VERSION ""

NS_ :

BS_:

BU_: VT3 VT2 VT1 Implement

BO_ 2565734142 Nxx: 8 Vector__XXX
 SG_ FirstSpecificParametricId m131 : 16|8@1+ (1,0) [0|0] "" Vector__XXX
 SG_ FirstGeneralParametricId m128 : 8|8@1+ (1,0) [0|0] "" Vector__XXX
 SG_ FirstSpecificParametric m132 : 16|16@1+ (1,0) [0|0] "" Vector__XXX
 SG_ FirstGeneralParametric m129 : 8|16@1+ (1,0) [0|0] "" Vector__XXX
 SG_ FailureReasonCode m194 : 24|8@1+ (1,0) [0|0] "" Vector__XXX
 SG_ Status m194 : 16|2@1+ (1,0) [0|0] "" Vector__XXX
 SG_ NameOfCF m192 : 16|64@1+ (1,0) [0|0] "" Vector__XXX
 SG_ NumberOfSaOrNamePairs m67 : 16|8@1+ (1,0) [0|250] "" Vector__XXX
 SG_ NIECUPort m64 : 8|4@1+ (1,0) [0|15] "" Vector__XXX
 SG_ FilterMode m1 : 16|8@1+ (1,0) [0|255] "" Vector__XXX
 SG_ FromPort m0 : 12|4@1+ (1,0) [0|15] "" Vector__XXX
 SG_ ToPort m0 : 8|4@1+ (1,0) [0|15] "" Vector__XXX
 SG_ ControlByte M : 0|8@1+ (1,0) [0|255] "" Vector__XXX

BO_ 2565799678 ACL: 8 Vector__XXX
 SG_ ArbitraryAddressCapable : 63|1@1+ (1,0) [0|1] "" Vector__XXX
 SG_ IndustryGroup M : 60|3@1+ (1,0) [0|7] "" Vector__XXX
 SG_ VehicleSystemInstance : 56|4@1+ (1,0) [0|15] "" Vector__XXX
 SG_ VehicleSystem m0 : 49|7@1+ (1,0) [0|127] "" Vector__XXX
 SG_ VehicleSystem5 m5 : 49|7@1+ (1,0) [0|127] "" Vector__XXX
 SG_ VehicleSystem4 m4 : 49|7@1+ (1,0) [0|127] "" Vector__XXX
 SG_ VehicleSystem3 m3 : 49|7@1+ (1,0) [0|127] "" Vector__XXX
 SG_ VehicleSystem2 m2 : 49|7@1+ (1,0) [0|127] "" Vector__XXX
 SG_ VehicleSystem1 m1 : 49|7@1+ (1,0) [0|127] "" Vector__XXX
 SG_ Function : 40|8@1+ (1,0) [0|255] "" Vector__XXX
 SG_ FunctionInstance : 35|5@1+ (1,0) [0|31] "" Vector__XXX
 SG_ ECUInstance : 32|3@1+ (1,0) [0|7] "" Vector__XXX
 SG_ ManufacturerCode : 21|11@1+ (1,0) [0|2047] "" Vector__XXX
 SG_ IdentityNumber : 0|21@1+ (1,0) [0|2097152] "" Vector__XXX

BO_ 2566838526 CA: 9 Vector__XXX
 SG_ AddressAssignment : 64|8@1+ (1,0) [0|255] "" Vector__XXX
 SG_ ArbitraryAddressCapable : 63|1@1+ (1,0) [0|1] "" Vector__XXX
 SG_ IndustryGroup M : 60|3@1+ (1,0) [0|7] "" Vector__XXX
 SG_ VehicleSystemInstance : 56|4@1+ (1,0) [0|15] "" Vector__XXX
 SG_ VehicleSystem1 m1 : 49|7@1+ (1,0) [0|127] "" Vector__XXX
 SG_ VehicleSystem2 m2 : 49|7@1+ (1,0) [0|127] "" Vector__XXX
 SG_ VehicleSystem3 m3 : 49|7@1+ (1,0) [0|127] "" Vector__XXX
 SG_ VehicleSystem4 m4 : 49|7@1+ (1,0) [0|127] "" Vector__XXX
 SG_ VehicleSystem5 m5 : 49|7@1+ (1,0) [0|127] "" Vector__XXX
 SG_ VehicleSystem m0 : 49|7@1+ (1,0) [0|127] "" Vector__XXX
 SG_ Function : 40|8@1+ (1,0) [0|255] "" Vector__XXX
 SG_ FunctionInstance : 35|5@1+ (1,0) [0|31] "" Vector__XXX
 SG_ ECUInstance : 32|3@1+ (1,0) [0|7] "" Vector__XXX
 SG_ ManufacturerCode : 21|11@1+ (1,0) [0|2047] "" Vector__XXX
 SG_ IdentityNumber : 0|21@1+ (1,0) [0|2097152] "" Vector__XXX

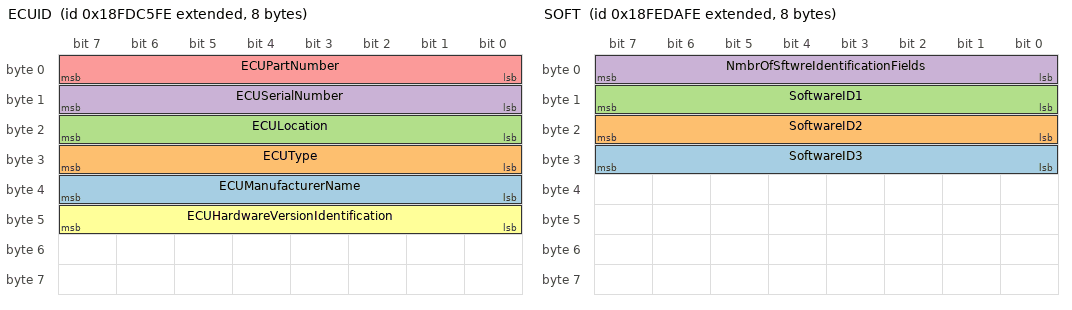
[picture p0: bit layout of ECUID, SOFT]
BO_ 2566768126 ECUID: 8 Vector__XXX
 SG_ ECUManufacturerName : 32|8@1+ (1,0) [0|255] "" Vector__XXX
 SG_ ECUType : 24|8@1+ (1,0) [0|255] "" Vector__XXX
 SG_ ECULocation : 16|8@1+ (1,0) [0|255] "" Vector__XXX
 SG_ ECUSerialNumber : 8|8@1+ (1,0) [0|255] "" Vector__XXX
 SG_ ECUPartNumber : 0|8@1+ (1,0) [0|255] "" Vector__XXX
 SG_ ECUHardwareVersionIdentification : 40|8@1+ (1,0) [0|255] "" Vector__XXX

BO_ 2566839038 SOFT: 8 Vector__XXX
 SG_ SoftwareID3 : 24|8@1+ (1,0) [0|255] "" Vector__XXX
 SG_ SoftwareID2 : 16|8@1+ (1,0) [0|255] "" Vector__XXX
 SG_ SoftwareID1 : 8|8@1+ (1,0) [0|255] "" Vector__XXX
 SG_ NmbrOfSftwreIdentificationFields : 0|8@1+ (1,0) [0|250] "steps" Vector__XXX

BO_ 2566834942 DM1: 22 Vector__XXX
 SG_ DTC5 : 144|32@1+ (1,0) [0|4294967295] "" Vector__XXX
 SG_ DTC4 : 112|32@1+ (1,0) [0|4294967295] "" Vector__XXX
 SG_ DTC3 : 80|32@1+ (1,0) [0|4294967295] "" Vector__XXX
 SG_ DTC2 : 48|32@1+ (1,0) [0|4294967295] "" Vector__XXX
 SG_ DTC1 : 16|32@1+ (1,0) [0|4294967295] "" Vector__XXX

BO_ 2566835198 DM2: 22 Vector__XXX
 SG_ DTC5 : 144|32@1+ (1,0) [0|4294967295] "" Vector__XXX
 SG_ DTC4 : 112|32@1+ (1,0) [0|4294967295] "" Vector__XXX
 SG_ DTC3 : 80|32@1+ (1,0) [0|4294967295] "" Vector__XXX
 SG_ DTC2 : 48|32@1+ (1,0) [0|4294967295] "" Vector__XXX
 SG_ DTC1 : 16|32@1+ (1,0) [0|4294967295] "" Vector__XXX

BO_ 2566734590 ICC: 8 Vector__XXX
 SG_ CertLaboratoryType_FirstDef m0 : 9|3@1+ (1,0) [0|7] "" Vector__XXX
 SG_ TestProtocolRevision_MSBits m1 : 11|2@1+ (1,0) [0|0] "" Vector__XXX
 SG_ MessageRevision M : 47|1@1+ (1,0) [0|0] "" Vector__XXX
 SG_ CertificationReferenceNumber : 48|16@1+ (1,0) [0|65535] "" Vector__XXX
 SG_ CertTypeTaskController m0 : 39|1@1+ (1,0) [0|1] "" Vector__XXX
 SG_ CertTypeTCWorkingSetMaster m0 : 38|1@1+ (1,0) [0|1] "" Vector__XXX
 SG_ CertTypeTCWorkingSetMember m0 : 37|1@1+ (1,0) [0|1] "" Vector__XXX
 SG_ CertTypeFileServer m0 : 36|1@1+ (1,0) [0|1] "" Vector__XXX
 SG_ CertTypeGPSReceiver m0 : 35|1@1+ (1,0) [0|1] "" Vector__XXX
 SG_ CertTypeMinimumECU m0 : 31|1@1+ (1,0) [0|1] "" Vector__XXX
 SG_ CertTypeTECUClass1 m0 : 30|1@1+ (1,0) [0|1] "" Vector__XXX
 SG_ CertTypeTECUClass2 m0 : 29|1@1+ (1,0) [0|1] "" Vector__XXX
 SG_ CertTypeTECUClass3 m0 : 28|1@1+ (1,0) [0|1] "" Vector__XXX
 SG_ CertTypeClass3ECU m0 : 27|1@1+ (1,0) [0|1] "" Vector__XXX
 SG_ CertTypeVirtualTerminal m0 : 26|1@1+ (1,0) [0|1] "" Vector__XXX
 SG_ CertTypeVTWorkingSetMaster m0 : 25|1@1+ (1,0) [0|1] "" Vector__XXX
 SG_ CertTypeVTWorkingSetMember m0 : 24|1@1+ (1,0) [0|1] "" Vector__XXX
 SG_ CertificationLaboratoryID : 13|11@1+ (1,0) [0|2047] "" Vector__XXX
 SG_ CertLaboratoryType_SecondDef m1 : 9|2@1+ (1,0) [0|3] "" Vector__XXX
 SG_ TestProtocolRevision : 6|3@1+ (1,0) [0|7] "" Vector__XXX
 SG_ TestProtocolPublicationYear : 0|6@1+ (1,2000) [2000|2061] "year" Vector__XXX

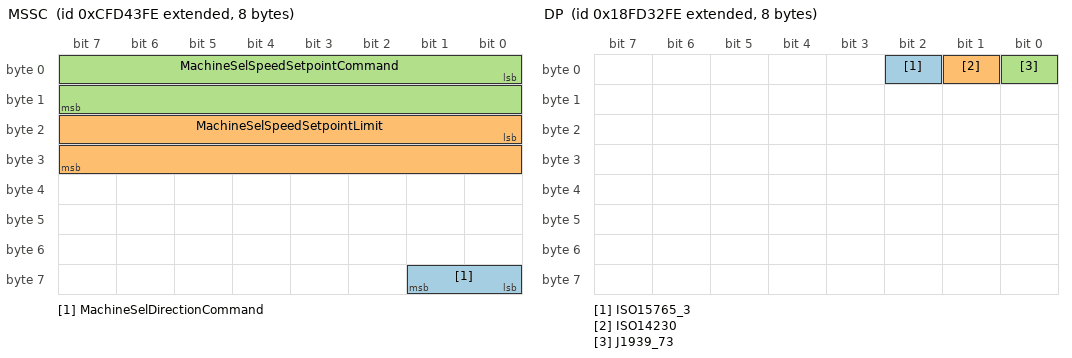
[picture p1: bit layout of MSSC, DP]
BO_ 2365408254 MSSC: 8 Vector__XXX
 SG_ MachineSelDirectionCommand : 56|2@1+ (1,0) [0|3] "" Vector__XXX
 SG_ MachineSelSpeedSetpointLimit : 16|16@1+ (0.001,0) [0|64255] "m/s" Vector__XXX
 SG_ MachineSelSpeedSetpointCommand : 0|16@1+ (0.001,0) [0|64255] "m/s" Vector__XXX

BO_ 2566730494 DP: 8 Vector__XXX
 SG_ ISO15765_3 : 2|1@1+ (1,0) [0|1] "" Vector__XXX
 SG_ ISO14230 : 1|1@1+ (1,0) [0|1] "" Vector__XXX
 SG_ J1939_73 : 0|1@1+ (1,0) [0|1] "" Vector__XXX

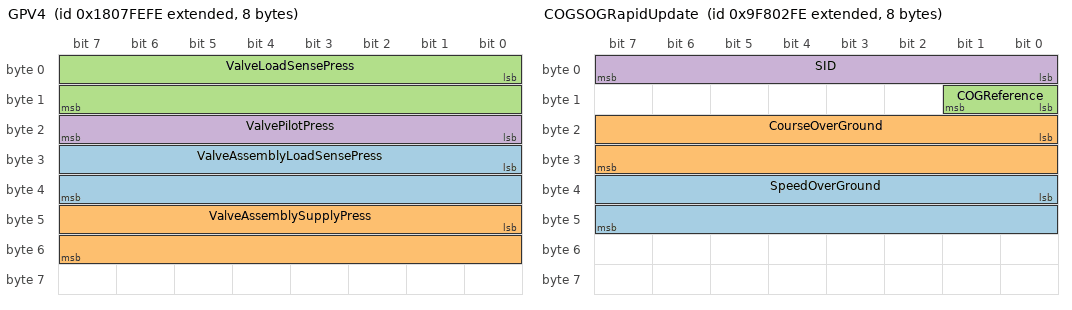
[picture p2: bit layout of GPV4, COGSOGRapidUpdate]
BO_ 2550660862 GPV4: 8 Vector__XXX
 SG_ ValveAssemblyLoadSensePress : 24|16@1+ (5,0) [0|321275] "kPa" Vector__XXX
 SG_ ValveAssemblySupplyPress : 40|16@1+ (5,0) [0|321275] "kPa" Vector__XXX
 SG_ ValveLoadSensePress : 0|16@1+ (5,0) [0|321275] "kPa" Vector__XXX
 SG_ ValvePilotPress : 16|8@1+ (16,0) [0|4000] "kPa" Vector__XXX

BO_ 2364547838 MSS: 9 Vector__XXX
 SG_ MachineSelectedSpeedLimitStatus : 61|3@1+ (1,0) [0|7] "" Vector__XXX
 SG_ MachineSelectedSpeedSource : 58|3@1+ (1,0) [0|7] "" Vector__XXX
 SG_ MachineSelectedDirection : 56|2@1+ (1,0) [0|3] "" Vector__XXX
 SG_ MachineSelectedDistance : 16|32@1+ (0.001,0) [0|4211081.215] "m" Vector__XXX
 SG_ MachineSelectedSpeed : 0|16@1+ (0.001,0) [0|65.535] "m/s" Vector__XXX

BO_ 2566835454 DM3: 0 Vector__XXX

BO_ 2365391616 IOS: 8 Vector__XXX
 SG_ ImplementOperatingStateCmd : 56|2@1+ (1,0) [0|3] "" Vector__XXX

BO_ 2365391360 AISO: 8 Vector__XXX
 SG_ StopAllImplOpTransitionNum : 48|8@1+ (1,0) [0|0] "" Vector__XXX
 SG_ StopAllImplementOperations : 56|2@1- (1,0) [0|3] "" Vector__XXX

BO_ 2314732286 COGSOGRapidUpdate: 8 Vector__XXX
 SG_ SpeedOverGround : 32|16@1+ (0.01,0) [0|655.32] "m/s" Vector__XXX
 SG_ CourseOverGround : 16|16@1+ (0.0001,0) [0|6.28318] "rad" Vector__XXX
 SG_ COGReference : 8|2@1+ (1,0) [0|3] "" Vector__XXX
 SG_ SID : 0|8@1+ (1,0) [0|252] "" Vector__XXX

BO_ 2358181630 SCMCC: 8 Vector__XXX
 SG_ MaxDesignatorStringLength m144 : 32|16@1+ (1,0) [0|65535] "" Vector__XXX
 SG_ BusyFlagParsing m149 : 33|1@1+ (1,0) [0|1] "" Vector__XXX
 SG_ ReceivedTAN m50 : 32|8@1+ (1,0) [0|255] "" Vector__XXX
 SG_ RecordedFunctionValue m51 : 32|32@1+ (1,0) [0|4294967295] "" Vector__XXX
 SG_ BusyFlagMemoryAccess m149 : 32|1@1+ (1,0) [0|1] "" Vector__XXX
 SG_ ExecutionIndicationResponseError m50 : 24|8@1+ (1,0) [0|255] "" Vector__XXX
 SG_ TAN m51 : 24|8@1+ (1,0) [0|255] "" Vector__XXX
 SG_ SequenceState m149 : 24|8@1+ (1,0) [0|255] "" Vector__XXX
 SG_ ReasonIndicator m48 : 24|8@1+ (1,0) [0|255] "" Vector__XXX
 SG_ GraphicsHeight m144 : 24|8@1+ (1,0) [32|255] "" Vector__XXX
 SG_ FunctionExecutionState m50 : 22|2@1+ (1,0) [0|3] "" Vector__XXX
 SG_ FunctionExecutionStateAck m52 : 22|2@1+ (1,0) [0|3] "" Vector__XXX
 SG_ StateID m50 : 16|6@1+ (1,0) [0|63] "" Vector__XXX
 SG_ ActualConfigurationLabel m0 : 16|8@1+ (1,0) [0|255] "" Vector__XXX
 SG_ ActualVersionLabel m0 : 16|8@1+ (1,0) [0|255] "" Vector__XXX
 SG_ GraphicsWidth m144 : 16|8@1+ (1,0) [32|255] "" Vector__XXX
 SG_ RecordedStateID m51 : 16|6@1+ (1,0) [0|63] "" Vector__XXX
 SG_ SequenceNumber m149 : 16|8@1+ (1,0) [0|255] "" Vector__XXX
 SG_ ObjectIdOfFirstFaultyObject m4 : 16|16@1+ (1,0) [0|65535] "" Vector__XXX
 SG_ RecordedFunctionID m51 : 8|8@1+ (1,0) [0|255] "" Vector__XXX
 SG_ MemoryStatus m145 : 8|8@1+ (1,0) [0|1] "" Vector__XXX
 SG_ VersionResponseError m1M : 8|8@1+ (1,0) [0|255] "" Vector__XXX
 SG_ ConfigLabelResponseError m2M : 8|8@1+ (1,0) [0|255] "" Vector__XXX
 SG_ TransferResponseError m3 : 8|8@1+ (1,0) [0|255] "" Vector__XXX
 SG_ ActivationResponseError m4 : 8|8@1+ (1,0) [0|255] "" Vector__XXX
 SG_ SCMState m149 : 8|8@1+ (1,0) [0|2] "" Vector__XXX
 SG_ FunctionID m50 : 8|8@1+ (1,0) [0|255] "" Vector__XXX
 SG_ SCVersion m144 : 8|8@1+ (1,0) [0|255] "" Vector__XXX
 SG_ CommandedSCCState m48 : 8|8@1+ (1,0) [0|1] "" Vector__XXX
 SG_ DeleteCommandResponseError m5 : 8|8@1+ (1,0) [0|255] "" Vector__XXX
 SG_ StoreCommandError m6 : 8|8@1+ (1,0) [0|255] "" Vector__XXX
 SG_ LoadResponseError m7 : 8|8@1+ (1,0) [0|255] "" Vector__XXX
 SG_ MessageCode M : 0|8@1+ (1,0) [0|255] "" Vector__XXX

BO_ 2358116094 SCCCM: 8 Vector__XXX
 SG_ OperatorConfirmationRequired3 m3 : 63|1@1+ (1,0) [0|1] "" Vector__XXX
 SG_ ClientFunctionErrorStatuts3 m3 : 56|4@1+ (1,0) [0|15] "" Vector__XXX
 SG_ IDOfFaultyClientFunction3 m3 : 48|8@1+ (1,0) [0|255] "" Vector__XXX
 SG_ OperatorConfirmationRequired2 m2 : 47|1@1+ (1,0) [0|1] "" Vector__XXX
 SG_ ClientFunctionErrorStatuts2 m2 : 40|4@1+ (1,0) [0|15] "" Vector__XXX
 SG_ ReceivedTAN m52 : 32|8@1+ (1,0) [0|255] "" Vector__XXX
 SG_ FunctionValue m0 : 32|32@1+ (1,0) [0|4294967295] "" Vector__XXX
 SG_ IDOfFaultyClientFunction2 m2 : 32|8@1+ (1,0) [0|255] "" Vector__XXX
 SG_ ClientFunctonErrorState m150 : 32|8@1+ (1,0) [0|255] "" Vector__XXX
 SG_ OperatorConfirmationRequired1 m1 : 31|1@1+ (1,0) [0|1] "" Vector__XXX
 SG_ TAN m50 : 24|8@1+ (1,0) [0|255] "" Vector__XXX
 SG_ ClientExecutionError m52 : 24|8@1+ (1,0) [0|255] "" Vector__XXX
 SG_ ClientFunctionErrorStatuts1 m1 : 24|4@1+ (1,0) [0|15] "" Vector__XXX
 SG_ ClientAbortError m49 : 24|8@1+ (1,0) [0|255] "" Vector__XXX
 SG_ SequenceState m150 : 24|8@1+ (1,0) [0|255] "" Vector__XXX
 SG_ FunctionExecutionState m50M : 22|2@1+ (1,0) [0|3] "" Vector__XXX
 SG_ NewFunctionExecutionState m52 : 22|2@1+ (1,0) [0|3] "" Vector__XXX
 SG_ NewStateID m52 : 16|6@1+ (1,0) [0|63] "" Vector__XXX
 SG_ IDOfFaultyClientFunction1 m1 : 16|8@1+ (1,0) [0|255] "" Vector__XXX
 SG_ StateID m50 : 16|6@1+ (1,0) [0|63] "" Vector__XXX
 SG_ SequenceNumber m150 : 16|8@1+ (1,0) [0|255] "" Vector__XXX
 SG_ NumberOfFaultyFunctions m53M : 8|8@1+ (1,0) [0|255] "" Vector__XXX
 SG_ RecordedFunctionID m52 : 8|8@1+ (1,0) [0|255] "" Vector__XXX
 SG_ SCCState m150 : 8|8@1+ (1,0) [0|2] "" Vector__XXX
 SG_ FunctionID m50 : 8|8@1+ (1,0) [0|255] "" Vector__XXX
 SG_ MemoryRequired m145 : 8|32@1+ (1,0) [0|4294967295] "bytes" Vector__XXX
 SG_ AddressSCCWSM m4 : 8|8@1+ (1,0) [0|253] "" Vector__XXX
 SG_ DeleteCommandType m5 : 8|8@1+ (1,0) [0|1] "" Vector__XXX
 SG_ MessageCode M : 0|8@1+ (1,0) [0|255] "" Vector__XXX

BO_ 2559835902 NM: 8 Vector__XXX
 SG_ ManufacturerCodeQualifierFlag m0 : 8|1@1+ (1,0) [0|1] "" Vector__XXX
 SG_ ECUInstanceQualifierFlag m0 : 9|1@1+ (1,0) [0|1] "" Vector__XXX
 SG_ FunctionInstanceQualifierFlag m0 : 10|1@1+ (1,0) [0|1] "" Vector__XXX
 SG_ FunctionQualifierFlag m0 : 11|1@1+ (1,0) [0|1] "" Vector__XXX
 SG_ VehicleSystemQualifierFlag m0 : 12|1@1+ (1,0) [0|1] "" Vector__XXX
 SG_ VehicleSystemInstanceQualifierFl m0 : 13|1@1+ (1,0) [0|1] "" Vector__XXX
 SG_ IndustryGroupQualifierFlag m0 : 14|1@1+ (1,0) [0|1] "" Vector__XXX
 SG_ ArbitraryAddressCapableQualifier m0 : 15|1@1+ (1,0) [0|1] "" Vector__XXX
 SG_ NMControlModeIndicator M : 16|4@1+ (1,0) [0|15] "" Vector__XXX
 SG_ CommandManufacturerCode m0 : 21|11@1+ (1,0) [0|2047] "" Vector__XXX
 SG_ CommandECUInstance m0 : 32|3@1+ (1,0) [0|7] "" Vector__XXX
 SG_ CommandFunctionInstance m0 : 35|5@1+ (1,0) [0|31] "" Vector__XXX
 SG_ CommandFunction m0 : 40|8@1+ (1,0) [0|255] "" Vector__XXX
 SG_ CommandVehicleSystem m0 : 49|7@1+ (1,0) [0|127] "" Vector__XXX
 SG_ CommandIndustryGroup m0 : 60|3@1+ (1,0) [0|7] "" Vector__XXX
 SG_ CommandVehicleSystemInstance m0 : 56|4@1+ (1,0) [0|15] "" Vector__XXX
 SG_ CommandArbitraryAddressCapable m0 : 63|1@1+ (1,0) [0|1] "" Vector__XXX
 SG_ ErrorCode m4 : 0|8@1+ (1,0) [0|0] "" Vector__XXX
 SG_ NameChecksum m0 : 0|8@1+ (1,0) [0|0] "" Vector__XXX

BO_ 2566843646 VI: 8 Vector__XXX
 SG_ VehicleIdentificationNumber : 0|8@1+ (1,0) [0|255] "per byte" Vector__XXX

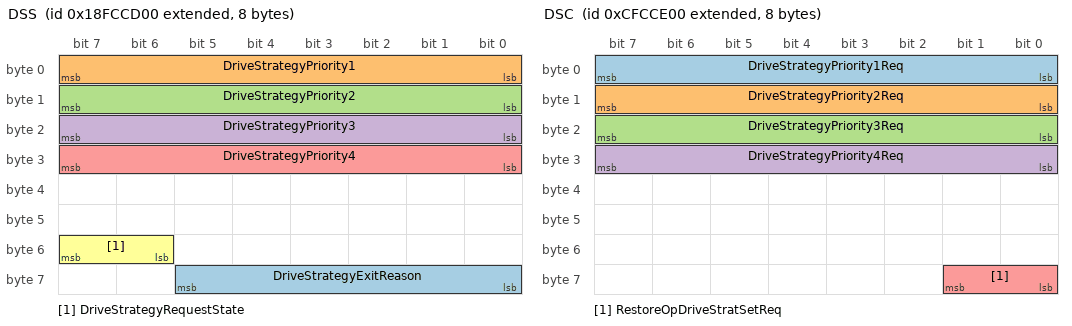
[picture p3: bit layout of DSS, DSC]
BO_ 2566704384 DSS: 8 Vector__XXX
 SG_ DriveStrategyExitReason : 56|6@1+ (1,0) [0|63] "" Vector__XXX
 SG_ DriveStrategyPriority1 : 0|8@1+ (1,0) [0|255] "" Vector__XXX
 SG_ DriveStrategyPriority2 : 8|8@1+ (1,0) [0|255] "" Vector__XXX
 SG_ DriveStrategyPriority3 : 16|8@1+ (1,0) [0|255] "" Vector__XXX
 SG_ DriveStrategyPriority4 : 24|8@1+ (1,0) [0|255] "" Vector__XXX
 SG_ DriveStrategyRequestState : 54|2@1+ (1,0) [0|3] "" Vector__XXX

BO_ 2365378048 DSC: 8 Vector__XXX
 SG_ DriveStrategyPriority1Req : 0|8@1+ (1,0) [0|255] "" Vector__XXX
 SG_ DriveStrategyPriority2Req : 8|8@1+ (1,0) [0|255] "" Vector__XXX
 SG_ DriveStrategyPriority3Req : 16|8@1+ (1,0) [0|255] "" Vector__XXX
 SG_ DriveStrategyPriority4Req : 24|8@1+ (1,0) [0|255] "" Vector__XXX
 SG_ RestoreOpDriveStratSetReq : 56|2@1+ (1,0) [0|3] "" Vector__XXX

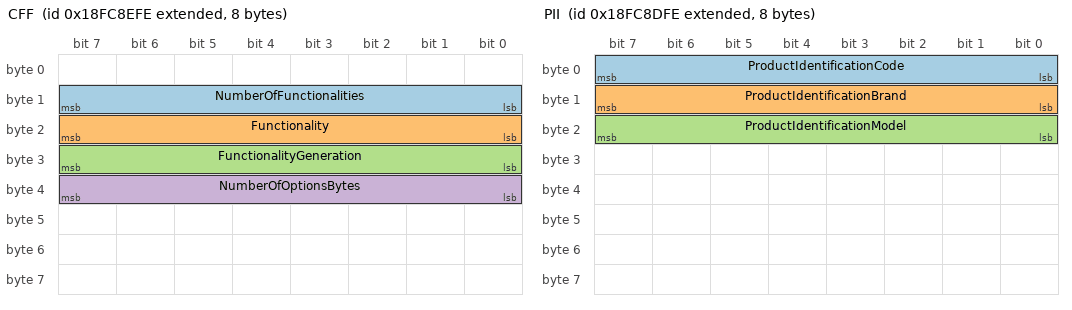
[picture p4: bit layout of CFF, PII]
BO_ 2566688510 CFF: 8 Vector__XXX
 SG_ NumberOfFunctionalities : 8|8@1- (1,0) [1|255] "" Vector__XXX
 SG_ Functionality : 16|8@1- (1,0) [0|255] "" Vector__XXX
 SG_ FunctionalityGeneration : 24|8@1- (1,0) [1|255] "" Vector__XXX
 SG_ NumberOfOptionsBytes : 32|8@1- (1,0) [0|255] "" Vector__XXX

BO_ 2566688254 PII: 8 Vector__XXX
 SG_ ProductIdentificationCode : 0|8@1- (1,0) [0|0] "" Vector__XXX
 SG_ ProductIdentificationBrand : 8|8@1- (1,0) [0|0] "" Vector__XXX
 SG_ ProductIdentificationModel : 16|8@1- (1,0) [0|0] "" Vector__XXX

CM_ BO_ 2565734142 "Used to access network interconnection ECU parametrics and database";
CM_ SG_ 2565734142 NumberOfSaOrNamePairs "The number of instances of Source Addresses and associated NAMEs included in the associated data content.";
CM_ SG_ 2565734142 NIECUPort "Port for Network PG";
CM_ SG_ 2565734142 FilterMode "Filter mode for Network PG";
CM_ SG_ 2565734142 FromPort "Source port for Network PG";
CM_ SG_ 2565734142 ToPort "Destination port for network PG";
CM_ BO_ 2565799678 "Address Claimed";
CM_ BO_ 2566838526 "Commanded Address";
CM_ SG_ 2566838526 AddressAssignment "The source address that is to be assigned to the CA that has the NAME corresponding to the one conveyed in the first eight bytes of this Commanded Address message.";
CM_ BO_ 2566768126 "ECU Identification Information";
CM_ SG_ 2566768126 ECULocation "The location of the ECU within a network.";
CM_ SG_ 2566768126 ECUSerialNumber "The serial number of the physical ECU.";
CM_ SG_ 2566768126 ECUPartNumber "The part number of the physical ECU.";
CM_ SG_ 2566768126 ECUHardwareVersionIdentification "The part number of the physical ECU.";
CM_ BO_ 2566839038 "Software Identification";
CM_ SG_ 2566839038 SoftwareID3 "Software ID";
CM_ SG_ 2566839038 SoftwareID2 "Software ID";
CM_ SG_ 2566839038 SoftwareID1 "Software ID";
CM_ SG_ 2566839038 NmbrOfSftwreIdentificationFields "Number of software identification designators represented in the software identification parameter group.";
CM_ BO_ 2566834942 "Active diagnostic trouble codes";
CM_ SG_ 2566834942 DTC5 "Diagnostic Trouble Code";
CM_ SG_ 2566834942 DTC4 "Diagnostic Trouble Code";
CM_ SG_ 2566834942 DTC3 "Diagnostic Trouble Code";
CM_ SG_ 2566834942 DTC2 "Diagnostic Trouble Code";
CM_ SG_ 2566834942 DTC1 "Diagnostic Trouble Code";
CM_ BO_ 2566835198 "Previously active diagnostic trouble codes";
CM_ SG_ 2566835198 DTC5 "Diagnostic Trouble Code";
CM_ SG_ 2566835198 DTC4 "Diagnostic Trouble Code";
CM_ SG_ 2566835198 DTC3 "Diagnostic Trouble Code";
CM_ SG_ 2566835198 DTC2 "Diagnostic Trouble Code";
CM_ SG_ 2566835198 DTC1 "Diagnostic Trouble Code";
CM_ BO_ 2566734590 "ISOBUS compliance certification";
CM_ SG_ 2566734590 CertLaboratoryType_FirstDef "Approving body for the certification laboratory.";
CM_ SG_ 2566734590 MessageRevision "This parameter distinguishes the format of the ISOBUS Compliance Certification message in the second 
edition from the format in the third and later editions.";
CM_ SG_ 2566734590 CertificationReferenceNumber "ISOBUS Compliance certification reference number";
CM_ SG_ 2566734590 CertTypeTaskController "ISOBUS Compliance certification type - Task Controller";
CM_ SG_ 2566734590 CertTypeTCWorkingSetMaster "ISOBUS Compliance certification type - TC working set master";
CM_ SG_ 2566734590 CertTypeTCWorkingSetMember "ISOBUS Compliance certification type - TC working set member";
CM_ SG_ 2566734590 CertTypeFileServer "ISOBUS Compliance certification type - File server";
CM_ SG_ 2566734590 CertTypeGPSReceiver "ISOBUS Compliance certification type - GPS receiver";
CM_ SG_ 2566734590 CertTypeMinimumECU "ISOBUS Compliance certification type - Minimum ECU";
CM_ SG_ 2566734590 CertTypeTECUClass1 "ISOBUS Compliance certification type - TECU Class 1";
CM_ SG_ 2566734590 CertTypeTECUClass2 "ISOBUS Compliance certification type - TECU Class 2";
CM_ SG_ 2566734590 CertTypeTECUClass3 "ISOBUS Compliance certification type - TECU Class 3";
CM_ SG_ 2566734590 CertTypeClass3ECU "ISOBUS Compliance certification type - Class 3 ECU";
CM_ SG_ 2566734590 CertTypeVirtualTerminal "ISOBUS Compliance certification type - Virtual terminal";
CM_ SG_ 2566734590 CertTypeVTWorkingSetMaster "ISOBUS Compliance certification type - VT working set master";
CM_ SG_ 2566734590 CertTypeVTWorkingSetMember "ISOBUS Compliance certification type - VT working set member";
CM_ SG_ 2566734590 CertificationLaboratoryID "ISOBUS Compliance certification laboratory ID";
CM_ SG_ 2566734590 CertLaboratoryType_SecondDef "Approving body for the certification laboratory.";
CM_ SG_ 2566734590 TestProtocolRevision "ISOBUS compliance certificate revision";
CM_ SG_ 2566734590 TestProtocolPublicationYear "ISOBUS compliance certification year";
CM_ BO_ 2365408254 "Machine Selected Speed Command";
CM_ SG_ 2365408254 MachineSelDirectionCommand "Machine selected direction command";
CM_ SG_ 2365408254 MachineSelSpeedSetpointLimit "Machine selected speed setpoint limit";
CM_ SG_ 2365408254 MachineSelSpeedSetpointCommand "Machine selected speed setpoint command";
CM_ BO_ 2566730494 "ECU diagnostic protocol";
CM_ SG_ 2566730494 ISO15765_3 "ISO 15765-3 (UDS on CAN)";
CM_ SG_ 2566730494 ISO14230 "ISO 14230 (KWP 2000 over K line)";
CM_ SG_ 2566730494 J1939_73 "J1939-73";
CM_ BO_ 2550660862 "General purpose valve load sense pressure";
CM_ SG_ 2550660862 ValveAssemblyLoadSensePress "The maximum pressure of a valve assembly's current collective load sense pressures where a valve assembly can ...";
CM_ SG_ 2550660862 ValveAssemblySupplyPress "Pressure of the hydraulic supply port to a valve assembly.";
CM_ SG_ 2550660862 ValveLoadSensePress "The maximum of the currently measured pressures of a valve's work port A and work port B.";
CM_ SG_ 2550660862 ValvePilotPress "Pressure of a valve's pilot supply port.";
CM_ BO_ 2364547838 "Machine selected speed";
CM_ SG_ 2364547838 MachineSelectedSpeedLimitStatus "Machine selected speed limit status";
CM_ SG_ 2364547838 MachineSelectedSpeedSource "Machine selected speed source";
CM_ SG_ 2364547838 MachineSelectedDirection "Machine selected direction";
CM_ SG_ 2364547838 MachineSelectedDistance "Machine selected Distance";
CM_ SG_ 2364547838 MachineSelectedSpeed "Machine selected Speed";
CM_ BO_ 2566835454 "Diagnostic data clear/reset of previously active DTCs.";
CM_ BO_ 2365391616 "Implement operating state command";
CM_ BO_ 2365391360 " All implements stop operations switch state";
CM_ SG_ 2365391360 StopAllImplOpTransitionNum "This parameter indicates the number of transitions from Permit (01) to Stop (00) since power up of 
the Stop all implement operations parameter. The parameter resets to zero on the next transition after 
reporting the maximum value.";
CM_ BO_ 2314732286 "This PGN is a single frame PGN that provides Course Over Ground(COG)and Speed Over Ground(SOG).

Being a single frame Msg,as opposed to other PGNs that include COG and SOG and are defined as multi-packet,this PGN lends itself to being transmitted more f";
CM_ SG_ 2314732286 CourseOverGround "The direction of the path over ground actually followed by a vessel.";
CM_ SG_ 2314732286 COGReference "0 = True, 
1 = Magnetic, 
2 = Error, 
3 = Null";
CM_ SG_ 2314732286 SID "An upward counting number used to tie related information together between different PGNs.For example,SID would be used to tie together COG,SOG and RAIM values to a given Pos.255=no valid Pos fix to tie it to.Range 0 to 250 for valid Pos fixes.";
CM_ BO_ 2358181630 "Sequence Control Master to Sequence Control Client";
CM_ SG_ 2358181630 MaxDesignatorStringLength "Maximum number of displayed characters for designator strings";
CM_ SG_ 2358181630 GraphicsHeight "Number of pixels on the Y axis for graphics objects";
CM_ SG_ 2358181630 GraphicsWidth "Number of pixels on the X axis for graphics objects";
CM_ SG_ 2358181630 ObjectIdOfFirstFaultyObject "Object ID of first faulty object";
CM_ SG_ 2358181630 MemoryStatus "Status of the SCMasterMemoryResponse";
CM_ SG_ 2358181630 VersionResponseError "Error code of the SCDVersionResponse";
CM_ SG_ 2358181630 ConfigLabelResponseError "Error code of SCDConfigurationLabelResponse";
CM_ SG_ 2358181630 TransferResponseError "Error code of the SCDTransferResponse";
CM_ SG_ 2358181630 SCMState "State of sending SCM";
CM_ SG_ 2358181630 SCVersion "Version of supported SC standard";
CM_ SG_ 2358181630 MessageCode "Message code of the SCMCC message";
CM_ BO_ 2358116094 "Sequence Control Client to Sequence Control Master";
CM_ SG_ 2358116094 ClientAbortError "Error code of a SCClientAbort";
CM_ SG_ 2358116094 MemoryRequired "Volatile memory required, number of bytes of the SCD to upload";
CM_ SG_ 2358116094 AddressSCCWSM "Source address of SCC's working set master";
CM_ BO_ 2566843646 "Byte: 1-n Vehicle Identification Number 
Delimiter (ASCII “*”)";
CM_ SG_ 2566843646 VehicleIdentificationNumber "Vehicle Identification Number (VIN) as assigned by the vehicle manufacturer.";
CM_ BO_ 2566704384 "Message sent from the tractor to the implement to indicate the current status, of the drive strategy priority 
structure, which indicates the priority of the multiple powertrain functions. ";
CM_ SG_ 2566704384 DriveStrategyExitReason "Parameter used to indicate why the drive strategy subsystem cannot currently accept remote commands or 
has most recently stopped accepting remote commands.";
CM_ SG_ 2566704384 DriveStrategyPriority1 "This parameter indicates the current Tractor drive strategy priority structure, which determines the balance 
between  fuel  economy/consumption  and  the  torque  reserve  of  the  engine.  This  parameter  indicates  the 
highest priority. ";
CM_ SG_ 2566704384 DriveStrategyPriority2 "This parameter indicates the current Tractor drive strategy priority structure, which determines the balance 
between  fuel  economy/consumption  and  the  torque  reserve  of  the  engine.  This  parameter  indicates 
 the second to highest priority. ";
CM_ SG_ 2566704384 DriveStrategyPriority3 "This parameter indicates the current Tractor drive strategy priority structure, which determines the balance 
between  fuel  economy/consumption  and  the  torque  reserve  of  the  engine.  This  parameter  indicates 
 the third to highest priority. ";
CM_ SG_ 2566704384 DriveStrategyPriority4 "This parameter indicates the current Tractor drive strategy priority structure, which determines the balance 
between  fuel  economy/consumption  and  the  torque  reserve  of  the  engine.  This  parameter  indicates  the 
lowest priority. ";
CM_ SG_ 2566704384 DriveStrategyRequestState "This  parmeter  reports  the  tractor's  state  associated  with  Drive  Strategy  requests  that  are 
transient/temporary/one-shot.";
CM_ SG_ 2365378048 DriveStrategyPriority1Req "This parameter used to request an alteration to the tractor drive strategy priority structure, which determines 
the  balance  between  fuel  economy/consumption  and  the  torque  reserve  of  the  engine - the highest priority request.";
CM_ SG_ 2365378048 DriveStrategyPriority2Req "This parameter used to request an alteration to the tractor drive strategy priority structure, which determines 
the  balance  between  fuel  economy/consumption  and  the  torque  reserve  of  the  engine - the second to highest priority request.";
CM_ SG_ 2365378048 DriveStrategyPriority3Req "This parameter used to request an alteration to the tractor drive strategy priority structure, which determines 
the  balance  between  fuel  economy/consumption  and  the  torque  reserve  of  the  engine - the third to highest priority request.";
CM_ SG_ 2365378048 DriveStrategyPriority4Req "This parameter used to request an alteration to the tractor drive strategy priority structure, which determines 
the  balance  between  fuel  economy/consumption  and  the  torque  reserve  of  the  engine - the lowest priority request.  ";
CM_ SG_ 2365378048 RestoreOpDriveStratSetReq "This parameter requests the drive strategy subsystem to restore the settings for drive strategy to the state 
before automation was ended. ";
CM_ BO_ 2566688510 "This message identifies all the functionalities, functionality generation and functionality options, supported by 
control functions.";
CM_ SG_ 2566688510 Functionality "This parameter reports which functionalities are supported by a control function connected to the ISO 11783 
network. ";
CM_ SG_ 2566688510 FunctionalityGeneration "This parameter reports the generation of the functionality provided by a control function connected to the ISO 11783 network.";
CM_ SG_ 2566688510 NumberOfOptionsBytes "This parameter reports the number of bytes that follow to report which options are supported by a functionality 
provided  by  a  control  function  connected  to  the  ISO  11783  network.";
CM_ BO_ 2566688254 "Product Identification Information: Each control function of a product shall respond with the same product identification information when it 
receives the Request PGN message for this PGN.";
CM_ SG_ 2566688254 ProductIdentificationCode "The Product Identification Code as assigned by the manufacturer correspondents with the number on the type 
plate of a product.";
CM_ SG_ 2566688254 ProductIdentificationBrand "Specifies  the  brand  of  a  product.  
The  combination  of  the  Product Identification Code and the Product Identification Brand shall make the product unique in the world.";
CM_ SG_ 2566688254 ProductIdentificationModel "The Product Identification Model specifies a unique product within a Brand. ";
BA_DEF_ SG_  "DDI" INT 0 65535;
BA_DEF_ BO_  "SingleFrame" INT 0 1;
BA_DEF_ BO_  "VFrameFormat" ENUM  "StandardCAN","ExtendedCAN","reserved","J1939PG","vector_leerstring";
BA_DEF_ BO_  "GenMsgSendType" ENUM  "cyclic","NotUsed","IfActive","NotUsed","NotUsed","NotUsed","NotUsed","NotUsed","noMsgSendType","vector_leerstring";
BA_DEF_ BO_  "GenMsgCycleTime" INT 0 3600000;
BA_DEF_ BO_  "GenMsgRequestable" INT 0 1;
BA_DEF_ BO_  "GenMsgCycleTimeFast" INT 0 3600000;
BA_DEF_ SG_  "SPN" INT 0 524287;
BA_DEF_ SG_  "GenSigSendType" ENUM  "Cyclic","OnWrite","OnWriteWithRepetition","OnChange","OnChangeWithRepetition","IfActive","IfActiveWithRepetition","NoSigSendType";
BA_DEF_ SG_  "SigType" ENUM  "Default","Range","RangeSigned","ASCII","Discrete","Control","ReferencePGN","DTC","StringDelimiter","StringLength","StringLengthControl","MessageCounter","MessageChecksum";
BA_DEF_ SG_  "GenSigStartValue" INT -2147483648 2147483647;
BA_DEF_ SG_  "SystemSignalLongSymbol" STRING ;
BA_DEF_DEF_  "DDI" 0;
BA_DEF_DEF_  "SingleFrame" 1;
BA_DEF_DEF_  "VFrameFormat" "J1939PG";
BA_DEF_DEF_  "GenMsgSendType" "noMsgSendType";
BA_DEF_DEF_  "GenMsgCycleTime" 0;
BA_DEF_DEF_  "GenMsgRequestable" 1;
BA_DEF_DEF_  "GenMsgCycleTimeFast" 0;
BA_DEF_DEF_  "SPN" 0;
BA_DEF_DEF_  "GenSigSendType" "NoSigSendType";
BA_DEF_DEF_  "SigType" "Default";
BA_DEF_DEF_  "GenSigStartValue" 0;
BA_DEF_DEF_  "SystemSignalLongSymbol" "";
BA_ "GenMsgCycleTime" BO_ 2365408254 100;
BA_ "GenMsgSendType" BO_ 2365408254 0;
BA_ "GenMsgCycleTime" BO_ 2550660862 100;
BA_ "GenMsgSendType" BO_ 2550660862 0;
BA_ "GenMsgCycleTime" BO_ 2314732286 250;
BA_ "GenMsgCycleTime" BO_ 2566704384 500;
BA_ "GenMsgSendType" BO_ 2566704384 0;
BA_ "GenMsgCycleTimeFast" BO_ 2365378048 100;
BA_ "GenMsgCycleTime" BO_ 2365378048 500;
BA_ "GenMsgSendType" BO_ 2365378048 0;
BA_ "SPN" SG_ 2565734142 FirstSpecificParametric 5597;
BA_ "SPN" SG_ 2565734142 NumberOfSaOrNamePairs 5602;
BA_ "SPN" SG_ 2565734142 NIECUPort 5593;
BA_ "SPN" SG_ 2565734142 FilterMode 5596;
BA_ "SigType" SG_ 2565734142 FilterMode 1;
BA_ "SPN" SG_ 2565734142 FromPort 5595;
BA_ "SPN" SG_ 2565734142 ToPort 5594;
BA_ "SigType" SG_ 2565734142 ControlByte 1;
BA_ "SPN" SG_ 2565799678 ArbitraryAddressCapable 2844;
BA_ "SPN" SG_ 2565799678 IndustryGroup 2846;
BA_ "SPN" SG_ 2565799678 VehicleSystemInstance 2843;
BA_ "SPN" SG_ 2565799678 Function 2841;
BA_ "SPN" SG_ 2565799678 FunctionInstance 2839;
BA_ "SPN" SG_ 2565799678 ECUInstance 2840;
BA_ "SigType" SG_ 2565799678 ManufacturerCode 1;
BA_ "SPN" SG_ 2565799678 ManufacturerCode 2838;
BA_ "SPN" SG_ 2565799678 IdentityNumber 2837;
BA_ "SigType" SG_ 2566838526 AddressAssignment 1;
BA_ "SPN" SG_ 2566838526 AddressAssignment 2847;
BA_ "SPN" SG_ 2566838526 ArbitraryAddressCapable 2844;
BA_ "SPN" SG_ 2566838526 IndustryGroup 2846;
BA_ "SPN" SG_ 2566838526 VehicleSystemInstance 2843;
BA_ "SPN" SG_ 2566838526 Function 2841;
BA_ "SPN" SG_ 2566838526 FunctionInstance 2839;
BA_ "SPN" SG_ 2566838526 ECUInstance 2840;
BA_ "SigType" SG_ 2566838526 ManufacturerCode 1;
BA_ "SPN" SG_ 2566838526 ManufacturerCode 2838;
BA_ "SPN" SG_ 2566838526 IdentityNumber 2837;
BA_ "SPN" SG_ 2566768126 ECUManufacturerName 4304;
BA_ "SigType" SG_ 2566768126 ECUManufacturerName 8;
BA_ "SigType" SG_ 2566768126 ECUType 8;
BA_ "SPN" SG_ 2566768126 ECUType 2904;
BA_ "SigType" SG_ 2566768126 ECULocation 8;
BA_ "SPN" SG_ 2566768126 ECULocation 2903;
BA_ "SigType" SG_ 2566768126 ECUSerialNumber 8;
BA_ "SPN" SG_ 2566768126 ECUSerialNumber 2902;
BA_ "SigType" SG_ 2566768126 ECUPartNumber 8;
BA_ "SPN" SG_ 2566768126 ECUPartNumber 2901;
BA_ "SigType" SG_ 2566768126 ECUHardwareVersionIdentification 8;
BA_ "SigType" SG_ 2566839038 SoftwareID3 8;
BA_ "SPN" SG_ 2566839038 SoftwareID3 234;
BA_ "SigType" SG_ 2566839038 SoftwareID2 8;
BA_ "SPN" SG_ 2566839038 SoftwareID2 234;
BA_ "SigType" SG_ 2566839038 SoftwareID1 8;
BA_ "SPN" SG_ 2566839038 SoftwareID1 234;
BA_ "SigType" SG_ 2566839038 NmbrOfSftwreIdentificationFields 1;
BA_ "SPN" SG_ 2566839038 NmbrOfSftwreIdentificationFields 965;
BA_ "SigType" SG_ 2566834942 DTC5 7;
BA_ "SigType" SG_ 2566834942 DTC4 7;
BA_ "SigType" SG_ 2566834942 DTC3 7;
BA_ "SigType" SG_ 2566834942 DTC2 7;
BA_ "SigType" SG_ 2566834942 DTC1 7;
BA_ "SigType" SG_ 2566835198 DTC5 7;
BA_ "SigType" SG_ 2566835198 DTC4 7;
BA_ "SigType" SG_ 2566835198 DTC3 7;
BA_ "SigType" SG_ 2566835198 DTC2 7;
BA_ "SigType" SG_ 2566835198 DTC1 7;
BA_ "SPN" SG_ 2566734590 CertLaboratoryType_FirstDef 4315;
BA_ "SPN" SG_ 2566734590 MessageRevision 7446;
BA_ "SPN" SG_ 2566734590 CertificationReferenceNumber 4330;
BA_ "SPN" SG_ 2566734590 CertTypeTaskController 4325;
BA_ "SPN" SG_ 2566734590 CertTypeTCWorkingSetMaster 4326;
BA_ "SPN" SG_ 2566734590 CertTypeTCWorkingSetMember 4327;
BA_ "SPN" SG_ 2566734590 CertTypeFileServer 4328;
BA_ "SPN" SG_ 2566734590 CertTypeGPSReceiver 4329;
BA_ "SPN" SG_ 2566734590 CertTypeMinimumECU 4317;
BA_ "SPN" SG_ 2566734590 CertTypeTECUClass1 4318;
BA_ "SPN" SG_ 2566734590 CertTypeTECUClass2 4319;
BA_ "SPN" SG_ 2566734590 CertTypeTECUClass3 4320;
BA_ "SPN" SG_ 2566734590 CertTypeClass3ECU 4321;
BA_ "SPN" SG_ 2566734590 CertTypeVirtualTerminal 4322;
BA_ "SPN" SG_ 2566734590 CertTypeVTWorkingSetMaster 4323;
BA_ "SPN" SG_ 2566734590 CertTypeVTWorkingSetMember 4324;
BA_ "SPN" SG_ 2566734590 CertificationLaboratoryID 4316;
BA_ "SPN" SG_ 2566734590 CertLaboratoryType_SecondDef 4315;
BA_ "SPN" SG_ 2566734590 TestProtocolRevision 4314;
BA_ "SPN" SG_ 2566734590 TestProtocolPublicationYear 4313;
BA_ "SigType" SG_ 2365408254 MachineSelDirectionCommand 4;
BA_ "SPN" SG_ 2365408254 MachineSelDirectionCommand 4312;
BA_ "SigType" SG_ 2365408254 MachineSelSpeedSetpointLimit 1;
BA_ "SPN" SG_ 2365408254 MachineSelSpeedSetpointLimit 4311;
BA_ "SigType" SG_ 2365408254 MachineSelSpeedSetpointCommand 1;
BA_ "SPN" SG_ 2365408254 MachineSelSpeedSetpointCommand 4310;
BA_ "SigType" SG_ 2550660862 ValveAssemblyLoadSensePress 1;
BA_ "SPN" SG_ 2550660862 ValveAssemblyLoadSensePress 4088;
BA_ "SigType" SG_ 2550660862 ValveAssemblySupplyPress 1;
BA_ "SPN" SG_ 2550660862 ValveAssemblySupplyPress 4089;
BA_ "SigType" SG_ 2550660862 ValveLoadSensePress 1;
BA_ "SPN" SG_ 2550660862 ValveLoadSensePress 4086;
BA_ "SigType" SG_ 2550660862 ValvePilotPress 1;
BA_ "SPN" SG_ 2550660862 ValvePilotPress 4087;
BA_ "SPN" SG_ 2364547838 MachineSelectedSpeedLimitStatus 4307;
BA_ "SPN" SG_ 2364547838 MachineSelectedSpeedSource 4308;
BA_ "SigType" SG_ 2364547838 MachineSelectedDirection 4;
BA_ "SPN" SG_ 2364547838 MachineSelectedDirection 4309;
BA_ "SPN" SG_ 2364547838 MachineSelectedDistance 4306;
BA_ "SPN" SG_ 2364547838 MachineSelectedSpeed 4305;
BA_ "SPN" SG_ 2365391616 ImplementOperatingStateCmd 5139;
BA_ "SPN" SG_ 2365391360 StopAllImplOpTransitionNum 7443;
BA_ "SPN" SG_ 2365391360 StopAllImplementOperations 5140;
BA_ "SigType" SG_ 2314732286 SpeedOverGround 1;
BA_ "SigType" SG_ 2314732286 CourseOverGround 1;
BA_ "SigType" SG_ 2314732286 COGReference 4;
BA_ "SigType" SG_ 2314732286 SID 1;
BA_ "GenSigStartValue" SG_ 2358181630 GraphicsHeight 32;
BA_ "SigType" SG_ 2358181630 ActualConfigurationLabel 9;
BA_ "SigType" SG_ 2358181630 ActualVersionLabel 9;
BA_ "GenSigStartValue" SG_ 2358181630 GraphicsWidth 32;
BA_ "SystemSignalLongSymbol" SG_ 2559835902 VehicleSystemInstanceQualifierFl "VehicleSystemInstanceQualifierFlag";
BA_ "SystemSignalLongSymbol" SG_ 2559835902 ArbitraryAddressCapableQualifier "ArbitraryAddressCapableQualifierFlag";
BA_ "SigType" SG_ 2566843646 VehicleIdentificationNumber 8;
BA_ "SPN" SG_ 2566843646 VehicleIdentificationNumber 237;
BA_ "SPN" SG_ 2566704384 DriveStrategyExitReason 5732;
BA_ "SPN" SG_ 2566704384 DriveStrategyPriority1 5727;
BA_ "SPN" SG_ 2566704384 DriveStrategyPriority2 5728;
BA_ "SPN" SG_ 2566704384 DriveStrategyPriority3 5729;
BA_ "SPN" SG_ 2566704384 DriveStrategyPriority4 5730;
BA_ "SPN" SG_ 2566704384 DriveStrategyRequestState 5731;
BA_ "SPN" SG_ 2365378048 DriveStrategyPriority1Req 5733;
BA_ "SPN" SG_ 2365378048 DriveStrategyPriority2Req 5734;
BA_ "SPN" SG_ 2365378048 DriveStrategyPriority3Req 5735;
BA_ "SPN" SG_ 2365378048 DriveStrategyPriority4Req 5736;
BA_ "SPN" SG_ 2365378048 RestoreOpDriveStratSetReq 5737;
BA_ "GenSigStartValue" SG_ 2566688510 NumberOfFunctionalities 1;
BA_ "GenSigStartValue" SG_ 2566688510 FunctionalityGeneration 1;
BA_ "SPN" SG_ 2566688254 ProductIdentificationCode 6699;
BA_ "SigType" SG_ 2566688254 ProductIdentificationCode 8;
BA_ "SPN" SG_ 2566688254 ProductIdentificationBrand 6701;
BA_ "SigType" SG_ 2566688254 ProductIdentificationBrand 8;
BA_ "SPN" SG_ 2566688254 ProductIdentificationModel 6701;
BA_ "SigType" SG_ 2566688254 ProductIdentificationModel 8;
VAL_ 2565734142 FirstSpecificParametricId 16 "NetworkInterconnectionUnitType" 15 "NumberOfPorts" 14 "UptimeSinceLastPowerOnReset " 13 "AverageNumOfMsgsFilteredPerSec" 12 "AverageNumOfMsgsForwardedPerSec" 11 "AverageNumOfMsgsReceivedPerSec" 10 "NumOfMsgsWithExcessTransitDelayTime " 9 "NumOfMsgsLostDueToBufferOverflow " 8 "AverageTransitDelayTime" 7 "MaxTransitDelayTime" 6 "MaxNumOfMsgsFilteredPerSec" 5 "MaxNumOfMsgsForwardedPerSec" 4 "MaxNumOfMsgsReceivedPerSec" 3 "NumberOfFilterDatabaseEntries" 2 "MaxFilterDatabaseSize" 1 "BufferSize" 0 "RequestAllParameters" ;
VAL_ 2565734142 FirstGeneralParametricId 16 "NetworkInterconnectionUnitType" 15 "NumberOfPorts" 14 "UptimeSinceLastPowerOnReset " 13 "AverageNumOfMsgsFilteredPerSec" 12 "AverageNumOfMsgsForwardedPerSec" 11 "AverageNumOfMsgsReceivedPerSec" 10 "NumOfMsgsWithExcessTransitDelayTime " 9 "NumOfMsgsLostDueToBufferOverflow " 8 "AverageTransitDelayTime" 7 "MaxTransitDelayTime" 6 "MaxNumOfMsgsFilteredPerSec" 5 "MaxNumOfMsgsForwardedPerSec" 4 "MaxNumOfMsgsReceivedPerSec" 3 "NumberOfFilterDatabaseEntries" 2 "MaxFilterDatabaseSize" 1 "BufferSize" 0 "RequestAllParameters" ;
VAL_ 2565734142 FailureReasonCode 255 "Not available" 4 "Request type not supported" 3 "Busy" 2 "Number of connections in NIU exceeded" 1 "Number of connections to NAME exceeded" 0 "Cannot find CF with short NAME" ;
VAL_ 2565734142 Status 1 "success" 0 "failure" ;
VAL_ 2565734142 NIECUPort 15 "Global (All ports)" 0 "Local" ;
VAL_ 2565734142 FilterMode 0 "BlockSpecificPGNs" 1 "PassSpecificPGNs" ;
VAL_ 2565734142 FromPort 15 "Global (All ports)" 0 "Local" ;
VAL_ 2565734142 ToPort 15 "Global (All ports)" 0 "Local" ;
VAL_ 2565734142 ControlByte 195 "CC_Response" 194 "OC_Response" 193 "CC_Request" 192 "OC_Request" 133 "SP_Reset" 132 "SP_Response" 131 "SP_Request" 130 "GP_Reset" 129 "GP_Response" 128 "GP_Request" 67 "NTX_Response" 66 "NTX_Request" 65 "NT_Response" 64 "NT_Request" 7 "MFDBNQ_Add" 6 "MFDB_CreateEntry" 5 "MFDB_SetMode_Obsolete" 4 "MFDB_Clear" 3 "MFDB_Delete" 2 "MFDB_Add" 1 "MFDB_Response" 0 "MFDB_Request" ;
VAL_ 2565799678 IndustryGroup 7 "Reserved for SAE" 5 "IndustrialProcessCtrlStationary" 4 "Marine" 3 "Construction" 2 "Agricultural and Forestry" 1 "On-Highway" 0 "Global" ;
VAL_ 2565799678 VehicleSystem 127 "Not Available" 0 "Non-specific System" ;
VAL_ 2565799678 VehicleSystem5 0 "Ind. Process Control Stationary" 127 "Not Available" ;
VAL_ 2565799678 VehicleSystem4 0 "Non-specific System" 127 "Not Available" 10 "System Tools" 20 "Safety Systems" 25 "Inter/Intranetwork Device" 30 "Electrical Distribution" 40 "Steering and Control Surfaces" 50 "Propulsion" 60 "Navigation" 70 "Communications" 80 "Instrumentation/General Systems (deprecate)" 90 "Internal Environment" 100 "Deck, Cargo and Fishing Equipment" 35 "Electrical Generation" 75 "Sensor Communication Interface" 85 "External Environment" 120 "Display" 125 "Entertainment" ;
VAL_ 2565799678 VehicleSystem3 0 "Non-specific System" 127 "Not Available" 1 "Skid Steer Loader" 2 "Articulated Dump Truck" 3 "Backhoe" 4 "Crawler" 5 "Excavator" 6 "Forklift" 7 "Four Wheel Drive Loader" 8 "Grader" ;
VAL_ 2565799678 VehicleSystem2 0 "Non-specific System" 127 "Not Available" 1 "Tractor" 2 "Tillage" 3 "Secondary Tillage" 4 "Planters/Seeders" 5 "Fertilizers" 6 "Sprayers" 7 "Harvesters" 8 "Root Harvesters" 9 "Forage" 10 "Irrigation" 11 "Transport/Trailer" 12 "Farm Yard Operations" 13 "Powered Auxiliary Device" 14 "Special Crops" 15 "Earth Work" 16 "Skidder" 17 "Sensor Systems" 19 "Timber Harvesters" 20 "Forwarders" 21 "Timber loaders" 22 "Timber Processing Machines" 23 "Mulchers" 24 "Utility Vehicles" 25 "Slurry Applicators" ;
VAL_ 2565799678 VehicleSystem1 0 "Non-specific System" 127 "Not Available" 1 "Tractor" 2 "Trailer" ;
VAL_ 2565799678 Function 43 "Transmission Display" 44 "Exhaust Emission Control" 45 "Vehicle Dynamic Stability Control" 46 "Oil Sensor Unit" 47 "Information System Controller" 48 "Ramp Control" 49 "Clutch/Converter Control" 50 "Auxiliary Heater" 51 "Forward-Looking Collision Warning System" 52 "Chassis Controller" 53 "Alternator/Charging System" 54 "Communications Unit, Cellular" 55 "Communications Unit, Satellite" 56 "Communications Unit, Radio" 57 "Steering Column Unit" 58 "Fan Drive Control" 59 "Starter" 60 "Cab Display" 61 "File Server/Printer" 62 "On-Board Diagnostic Unit" 63 "Engine Valve Controller" 64 "Endurance Braking" 65 "Gas Flow Measurement" 66 "I/O Controller" 67 "Electrical System Controller" 68 "Aftertreatment system gas measurement" 69 "Engine Emission Aftertreatement System" 70 "Auxiliary Regeneration Device" 71 "Transfer Case Control" 72 "Coolant Valve Controller" 73 "Rollover Detection Control" 74 "Lubrication System" 75 "Supplemental Fan" 76 "Temperature Sensor" 77 "Fuel Properties Sensor" 78 "Fire Suppression System" 79 "Reserved" 80 "Reserved" 81 "Reserved" 82 "Reserved" 83 "Reserved" 84 "Reserved" 85 "Reserved" 86 "Reserved" 87 "Reserved" 88 "Reserved" 89 "Reserved" 90 "Reserved" 91 "Reserved" 92 "Reserved" 93 "Reserved" 94 "Reserved" 95 "Reserved" 96 "Reserved" 97 "Reserved" 98 "Reserved" 99 "Reserved" 100 "Reserved" 0 "Engine" 1 "Auxiliary Power Unit (APU)" 2 "Electric Propulsion Control" 3 "Transmission" 4 "Battery Pack Monitor" 5 "Shift Control/Console" 6 "Power TakeOff - (Main or Rear)" 7 "Axle - Steering" 8 "Axle - Drive" 9 "Brakes - System Controller" 10 "Brakes - Steer Axle" 11 "Brakes - Drive Axle" 12 "Retarder - Engine" 13 "Retarder - Driveline" 14 "Cruise Control" 15 "Fuel System" 16 "Steering Controller" 17 "Suspension - Steer Axle" 18 "Suspension - Drive Axle" 19 "Instrument Cluster" 20 "Trip Recorder" 21 "Cab Climate Control" 22 "Aerodynamic Control" 23 "Vehicle Navigation" 24 "Vehicle Security" 25 "Network Interconnect ECU" 26 "Body Controller" 27 "Power TakeOff (Secondary or Front)" 28 "Off Vehicle Gateway" 29 "Virtual Terminal (in cab)" 30 "Management Computer" 31 "Propulsion Battery Charger" 32 "Headway Controller" 33 "System Monitor" 34 "Hydraulic Pump Controller" 35 "Suspension - System Controller" 36 "Pneumatic - System Controller" 37 "Cab Controller" 38 "Tire Pressure Control" 39 "Ignition Control Module" 40 "Seat Control" 41 "Lighting - Operator Controls" 42 "Water Pump Control" 101 "Reserved" 102 "Reserved" 103 "Reserved" 104 "Reserved" 105 "Reserved" 106 "Reserved" 107 "Reserved" 108 "Reserved" 109 "Reserved" 110 "Reserved" 111 "Reserved" 112 "Reserved" 113 "Reserved" 114 "Reserved" 115 "Reserved" 116 "Reserved" 117 "Reserved" 118 "Reserved" 119 "Reserved" 120 "Reserved" 121 "Reserved" 122 "Reserved" 123 "Reserved" 124 "Reserved" 125 "Reserved" 126 "Reserved" 127 "Reserved" ;
VAL_ 2565799678 ManufacturerCode 234 "Mondial electronic GmbH" 235 "SailorMade Marine Telemetry - Tetra Technology Ltd." 236 "Norac Systems International Inc" 237 "Agtron Enterprises Inc" 238 "ZF Friedrichshafen AG" 239 "May & Scofield Ltd" 240 "Vanair Mfg" 241 "Schneider Automation SAS " 242 "Kokusandenki Co. Ltd" 243 "eRide, Inc." 244 "Techno-Matic" 245 "Capstan Ag Systems, Inc." 246 "Class 1, Inc" 247 "ePULSE" 248 "Cooper Standard Automotive Active Systems Group" 264 "Autolync" 265 "MTS Sensor Technologie GmbH" 266 "International Thermal Research Ltd" 267 "Red Lion Controls, Inc" 268 "Accurate Technologies" 269 "Saft America Inc.,  Space & Defense Division" 270 "Tennant" 271 "Cole Hersee" 312 "Lectronix, Inc." 313 "Ilmor Engineering, Inc" 314 "CSM GmbH" 315 "Icom Incorporated" 316 "ITT Flow Control" 317 "Navtronics Bvba" 318 "SAT Plan" 319 "Cadec Global" 320 "Miedema Landbouwwerktuigenfabriek B.V." 321 "Ultra Electronics, Electrics" 322 "MICHENKA s.r.o." 323 "Mobileye Vision Technologies Ltd." 324 "Snap-on Diagnostics" 325 "ASM Automation Sensorik Messtechnik GmbH" 326 "Akron Brass Company" 327 "Sonceboz SA" 272 "Gross Mechanical Laboratories, Inc" 273 "Active Research Limited" 274 "LTW Technology Co., LTD" 275 "Navico Egersund AS" 276 "Aqua-Hot Heating Systems" 277 "LHP Telematics" 278 "Takata Electronics" 279 "Geometris LP" 280 "Leica Geosystems Pty Ltd" 299 "Rauch Landmaschinen GmbH" 300 "Systron Donner Automotive" 301 "Parker Hannifin (UK) Ltd FDE group" 302 "Nissin Kogyo Co., LTD" 303 "CTS Corporation" 304 "EmpirBus AB" 305 "NovAtel Inc" 306 "Sleipner Motor AB" 307 "MBW Technologies" 308 "Cyntrx" 309 "Krauss-Maffei Wegmann GmbH & Co. KG" 310 "TECNORD srl" 311 "Patrick Power Products" 281 "Precision Governors LLC" 282 "Medallion Instrumentation Systems" 283 "CWF Hamilton & Co Ltd" 284 "Mobile Tech Chile" 285 "Sea Recovery Corp" 286 "Coelmo srl" 287 "NTech Industries, Inc" 288 "Mitsubishi FUSO Truck & Bus Corp." 289 "Watlow" 290 "Kuebler GmbH" 291 "Groeneveld Transport Efficiency BV" 292 "IKUSI - Angel Iglesias S.A." 293 "Spyder Controls Corp." 294 "Grayhill Inc." 295 "BEP Marine" 296 "micro dynamics GmbH" 297 "Zonar Systems Inc" 298 "Holley Performance" 253 "Mobile Control Systems" 254 "GE Sensing" 255 "MEAS France" 256 "Tyco Electronics AMP" 257 "Honda Motor Co., Ltd" 258 "ARAG" 259 "Jetter AG" 260 "Reichhardt GmbH" 261 "Red Dot Corporation" 262 "HydraForce, Inc" 263 "IMMI" 223 "Vaueo Retarder Co., Ltd." 224 "EMMI Network, S.L." 225 "SKF" 226 "Monaco Coach Corporation" 227 "Lykketronic A/S" 228 "ZF Marine Electronics" 229 "Garmin International Inc." 230 "Saucon Technologies" 231 "Topcon Positioning Systems, Inc." 0 "Reserved" 1 "Allied Signal Inc." 2 "Allison Transmission, GMC" 3 "Ametek, US Gauge Division" 4 "Ametek-Dixson" 5 "AMP Inc." 6 "Berifors Electronics AB" 7 "Case Corp." 8 "Caterpillar Inc." 9 "Chrysler Corp." 10 "Cummins Engine Co." 11 "Dearborn Group Inc." 12 "Deere & Company, Precision Farming" 13 "Delco Electronics" 14 "Detroit Diesel Corporation" 15 "Dickey-John Corp." 16 "Eaton Corp." 17 "Eaton Corp. Res & Dev" 18 "Eaton Corp, Transmission Division" 19 "Eaton Corp. Trucking Info Services" 20 "Eaton Ltd" 21 "Echilin Inc., Midland Brake Inc." 22 "Ford Motor Co., Electronic Concepts $ Systems" 23 "Ford Motor Co., Heavy Truck" 24 "Ford Motor Co., Vehicle Controls" 25 "Daimler Trucks North America LLC" 26 "General Motors Corp., Service Technology Group" 27 "GMC" 28 "Grote Ind. Inc." 29 "Hino Motors Ltd." 30 "Isuzu Motors Ltd." 31 "J Pollak Corp." 32 "Jacobs Vehicle Systems" 33 "John Deere" 34 "Kelsey Hayes Co." 35 "Kenworth Truck Co." 36 "Lucas Ltd." 37 "Mack Trucks Inc." 38 "Micro Processor Systems Inc." 39 "Microfirm Inc." 40 "Motorola AIEG Inc." 41 "Motorola Inc." 42 "International Truck and Engine Corp. Engine Electronics" 43 "International Truck and Engine Corp. Vehicle Electronics" 44 "Nippondenso Co. Ltd." 45 "PACCAR" 46 "Noregon Systems, Inc" 47 "Phillips Semiconductor" 48 "Pollak Alphabet" 49 "RE America Inc." 50 "Robert Bosch Corp" 51 "Robert Bosch GmbH" 52 "Meritor Automotive, Inc." 53 "Continental Automotive Systems US, Inc." 54 "Meritor Wabco" 55 "Ryder System Inc." 56 "SAIC" 57 "Sauer-Danfoss Co." 58 "SPX Corporation, OTC Division" 59 "VES Inc." 60 "Volvo Trucks North America Inc." 61 "Volvo Truck Corp." 62 "Wabco" 63 "ZF Industries Inc." 64 "unused" 65 "MAN Nutzfahrzeuge AG" 66 "John Deere Construction Equipment Division" 67 "Funk Manufacturing Company" 68 "Scania" 69 "Trimble Navigation" 70 "Flex-Coil Limited" 71 "Vansco Electronics Ltd." 72 "Sisu Corporation" 73 "LeTourneau, Inc." 74 "Eaton Axle-Brake Division" 75 "Deere & Co. Agricultural Division" 76 "unused" 77 "Deere Power Systems Group" 78 "Frank W. Murphy Manufacturing, Inc." 79 "Daimler Benz AG - Engine Division (PBM)" 80 "Twin Disc, Inc." 81 "Fire Research Corp" 82 "Bobcat/Ingersoll-Rand" 83 "Bendix VORAD Technologies" 84 "New Holland UK Limited" 85 "Kohler Co." 86 "C.E. Niehoff & Company" 87 "J.C. Bamford Excavators Ltd (JCB)" 88 "Satloc Precision GPS" 89 "Kverneland Group, Electronics Division" 90 "Knorr-Bremse SfN GmbH" 91 "BSG Bodensee Steuergeraete GmbH" 92 "Ag-Chem Equipment Co., Inc." 93 "Perkins Engines Company Ltd." 94 "CNH Global N.V." 95 "Pacific Insight Electronics Corp." 96 "Mech@tronic IT GmbH" 97 "Ag Leader Technology, Inc." 98 "Mueller-Elektronik GmbH & Co." 99 "International Transmissions Ltd (ITL)" 100 "VDO Technik AG" 101 "Sensoria" 102 "AGCO GmbH & Co." 103 "CLAAS Agrosystems GmbH & Co. KG" 104 "Claas Selbstfahrende Erntemaschinen GmbH" 105 "Kiepe Elektrik GmbH & Co. KG" 106 "BAE Systems Controls, Inc." 107 "Grimme Landmaschinen GmbH & Co. KG" 108 "WTK-Elecktronik GmbH" 109 "TeeJet Technologies Denmark" 110 "EPIQ Sensor-Nite" 111 "Maschinenfabrik Bernard Krone GmbH" 112 "MECALAC" 113 "Stress-Tek, Inc." 114 "EControls, Inc." 115 "NACCO Materials Handling Group, Inc." 116 "BEELINE Technologies" 117 "HUSCO International" 118 "Intron GmbH" 119 "IntegriNautics" 120 "RDS Technology Ltd." 121 "HED (Hydro Electronic Devices, Inc.)" 122 "FG Wilson (Engineering) Limited" 123 "Basler Electric" 124 "Hydac Electronic" 125 "Nevada Automotive Test Center" 126 "Driver Tech" 127 "Holland USA" 128 "Gerhard Duecker GmbH & Co. KG" 129 "OMNEX Control Systems, Inc." 130 "Nido - Universal Machines B.V." 131 "ITT Industries" 132 "Mulag-Fahrzeugwerk" 133 "Bucher Schoerling GmbH" 134 "Iris Technology Ltd." 135 "Airmar Technology Corporation" 136 "Komatsu Ltd." 137 "Maretron" 138 "Georg Fritzmeier GmbH & Co. KG" 139 "Caterpillar Trimble Control Technologies (CTCT), LLC" 140 "Lowrance Electronics, Inc." 141 "Thales Navigation Ltd." 142 "TRW Automotive (Commercial Steering Systems)" 143 "W. Gmeiner GmbH & Co." 144 "Mercury Marine" 145 "MurCal Controls" 146 "Maxima Technologies" 147 "Nautibus Electronic GmbH" 148 "Blue Water Data, Inc." 149 "Holset" 150 "Fleetguard" 151 "Raven Industries Inc. - Flow Controls Division" 152 "elobau GmbH & Co. KG" 153 "Woodward, Industrial Controls Division" 154 "Westerbeke Corporation" 155 "Vetronix Corporation" 156 "ITT Industries - Cannon" 157 "ISSPRO Inc." 158 "Firestone Industrial Products Company" 159 "NTech Industries Inc." 160 "Nido" 161 "Offshore Systems (UK) Limited" 162 "Axiomatic Technologies" 163 "BRP Inc." 164 "DaimlerChrysler Off-Highway" 165 "CPAC Systems AB" 166 "Phoenix International" 167 "JLG Industries Inc." 168 "Xantrex" 169 "Marlin Technologies Inc." 170 "Computronics Corporation Ltd." 171 "Wachendorff Elektronik GmbH & Co. KG" 172 "Yanmar Marine USA" 173 "Ryeso, Inc." 174 "AB Volvo Penta" 175 "Veris Technologies, Inc." 176 "Moritz Aerospace" 177 "Diagnostic System Associates" 178 "Siemens VDO Automotive AG" 179 "TeeJet Technologies Denmark" 180 "Smart Power Systems" 181 "Coretronics, Inc." 182 "Vehicle Systems Engineering B.V." 183 "KDS Controls, Inc." 184 "EIA Electronics" 185 "Beede Electrical Instrument Company" 186 "Altronic, Inc." 187 "Air-Weigh" 188 "EMP Corp." 189 "QUALCOMM" 190 "Hella KGaA Hueck & Co." 191 "XRS Corporation" 192 "Floscan" 193 "Nobletec" 194 "TriMark Corporation" 195 "General Engine Products" 196 "LEMKEN GmbH & Co. KG" 197 "Mechron Power Systems" 198 "Mystic Valley Communications" 199 "Actia Corp." 200 "MGM Brakes" 201 "Disenos y Tecnologia S.A." 202 "Curtis Instruments, Inc." 203 "MILtronik GmbH" 204 "The Morey Corporation" 205 "SmarTire Systems Inc" 206 "port GmbH" 207 "Otto Engineering" 208 "Drew Technologies, Inc." 209 "Bell Equip. Co. SA (PTY) LTD" 210 "Iteris, Inc." 211 "DNA Group" 212 "Sure Power Industries, Inc." 213 "CNH Belgium N.V." 214 "MC elettronica Srl" 215 "Aetna Engineering/Fireboy-Xintex" 216 "Paneltronics Inc." 217 "RM Michaelides Software & Elektronik GmbH" 218 "Gits Manufacturing Company" 219 "Cat OEM Solutions" 220 "Beede Electrical Instrument Company, Inc." 221 "SiE" 222 "Generac Power Systems, Inc." 1850 "Teleflex" 1851 "Raymarine" 1852 "Navionics" 1853 "Japan Radio Co." 1854 "Northstar Technologies" 1855 "Furuno USA" 1856 "Trimble" 1857 "Simrad" 1858 "Litton" 1859 "Kvasar AB" 1860 "MMP" 1861 "Vector CANtech" 1862 "Sanshin" 1863 "Thomas G. Faria Co." 232 "TSD Integrated Controls" 233 "Yacht Monitoring Solutions Inc." 249 "Schaltbau GmbH" 250 "Kuhn Group" 251 "German Agricultural Society" 252 "Sensor-Technik Wiedemann GmbH" 328 "Qwerty Electronik AB" 329 "Deif A/S" 330 "Kidde Aerospace and Defense" 331 "Horton, Inc." 332 "HWH Corporation" 333 "Hadley Products Corporation" 334 "Takata-Petri AG" 335 "Evo Electric Ltd" 336 "APE s.r.o." 337 "Carraro S.p.A." 338 "GRAF-SYTECO" 339 "Competence Center ISOBUS e.V." 340 "Continental AG" 341 "Boning GmbH & Co" 342 "THOMAS MAGNETE GmbH" 343 "Baumer Group" 344 "Parvus Corporation" 345 "Korean Maritime University" 346 "Control Solutions" 347 "Honeywell" 348 "Amazonen Werke H. Dreyer" 349 "Suonentiet" 350 "Noris Marine Systems GmbH & Co KG" 351 "Thrane & Thrane" 352 "SAME DEUTZ-FAHR" 353 "Hegemon Electronics, Inc." 354 "Junkkari OY" 355 "Mastervolt International B.V." 356 "Fischer Panda Generators, Inc" 357 "Hardi International A/S" 358 "Victron Energy BV" 359 "Ludwig Bergmann GmbH" 360 "HJS Emission Technology GmbH & Co KG" 361 "InMach" 362 "Alois Poettinger Maschinenfabrik GmbH" 363 "BEI Duncan" 364 "OEM Controls Inc." 365 "Digi-Star, LLC" 366 "Viewnyx Corp." 367 "Fliegl Agrartechnik" 368 "HANSENHOF_electronic" 369 "Power Torque Engineering Ltd" 370 "Rolls-Royce Marine AS" 371 "Heinzmann GmbH & Co. KG" 373 "Electronic Design Inc." 374 "Northern Lights, Inc." 381 "B&G" 372 "Delphi" 375 "Williams Controls Inc." 376 "Quake Global" 377 "ifm electronic gmbh" 378 "Glendinning Marine Products" 379 "Yamabiko Corporation" 380 "Suntech International Ltd." 382 "National Agricultural and Food Research Organization" 383 "MCL Industries" 384 "Camano Light" 385 "Johnson Outdoor Marine Electronics" 386 "JLG Automation BVBA" 387 "Orscheln Products, LLC" 388 "Innomatix, LLC" 389 "Benchmark Electronics, Minnesota Division" 390 "Partech Inc." 391 "Electronic Design for Industry, Inc" 392 "Tianyuan Technology Co Ltd." 393 "Harvest Tec, Inc" 394 "Capi 2 Nederland BV" 395 "GENTEC S.R.L." 396 "Beyond Measure" 397 "Sanyo-kiki Co Ltd." 398 "Hilite International" 399 "ISEKI & Co., Ltd." 400 "Livorsi Marine" 401 "Torqeedo GmbH" 402 "Simma Software, Inc." 403 "Trackwell ADS, Inc." 404 "Com Nav Marine Ltd" 405 "Wema System AS" 406 "Vecima Networks Inc." 407 "Comtech Mobile Datacom" 408 "Corvus Energy Ltd." 409 "Transfluid S.r.L." 410 "COBO S.p.A. Divisione 3B6" 411 "Hy-Drive Technologies Ltd." 412 "WebTech Wireless Inc." 413 "Datapross Nijbroek bv" 414 "Cattron Group International" 415 "Valid Manufacturing Ltd." 416 "Kubota Corporation" 417 "KZValve" 418 "Intellistick Inc" 419 "Fusion Electronics Ltd" 420 "Vermeer Corporation, ACS Group" 421 "Vertex Standard Co., Ltd" 422 "True Heading AB" 423 "BSM Wireless, Inc." 424 "Odyne LLC" 425 "Methode Electronics Inc, MDI" 426 "Egersund Marine Electronics AS" 427 "em-trak Marine Electronics Ltd" 428 "Mfg_428" 429 "Rota Engineering Ltd." 455 "ADZ NAGANO GmbH" 456 "General Kinetics" 457 "RUSELPROM-ElectricDrive Ltd" 458 "Control Solutions, Inc." 459 "Alltek Marine Electronics Corp" 460 "San Giorgio S.E.I.N." 461 "HAWE Hydraulik SE" 462 "IHI Shibaura Machinery Corporation" 463 "PROBOTIQ" 464 "Leach International Corporation" 465 "Ashcroft Inc" 466 "Veethree Electronics and Marine LLC" 467 "Lely Industries N.V." 468 "Tyco Fire Protection Products" 469 "RA Consulting GmbH" 470 "SI-TEX Marine Electronics" 471 "Sea Cross Marine AB" 472 "Tenneco Inc." 473 "Boss Industries, Inc." 474 "Persen Technologies Inc." 475 "GME" 476 "Hummingbird Marine Electronics" 477 "OilQuick AB" 478 "OceanSat BV" 479 "Vapor Bus International" 430 "Auteq Telematica S.A." 431 "Tohatsu Corporation" 432 "S&A Systems, Inc." 433 "Rowe Electronics" 434 "Stored Energy Systems" 435 "Zunhammer GmbH" 436 "Kinze Manufacturing" 437 "Digital Yacht Limited" 438 "Comar Systems Ltd" 439 "Hyundai Heavy Industries" 440 "Cummins Power Generation" 441 "PTG Reifendruckregelsysteme GmbH" 442 "Horsch Maschinen GmbH" 443 "SignalQuest, Inc." 444 "ITT Power Solutions" 445 "KAT MECHATRONIC, Electronic Product Division" 446 "CertTech, L.L.C." 447 "Great Plains Mfg." 448 "Stanadyne Corporation, Electronics Systems" 449 "Polaris Industries Inc" 450 "Dycor Technologies Ltd." 451 "Parker Hannifin Corp" 452 "WIKA Alexander Wiegand SE & Co. KG" 453 "Cooper Bussmann" 454 "NGK Spark Plug Co. Ltd" 480 "EnerDel, Inc." 481 "Chetco Digital Instruments" 482 "Tricon Electronics" 483 "Valeo" 484 "Headsight Inc." 485 "MATT automotive" 486 "Westport Innovations Inc." 487 "DSE Test Solutions A/S" 488 "The Charles Machine Works, Inc." 489 "Appareo Systems" 490 "QuikQ" 491 "Penny and Giles Ltd" 492 "Inergy Automotive Systems" 493 "Watcheye" 494 "Synerject" 495 "HOLMER Maschinenbau GmbH" 496 "W. Gessmann GmbH" 497 "SENTRON Sistemas Embarcados" 498 "Innovative Design Solutions, Inc." 499 "LCJ Capteurs" 500 "Oxbo International Corporation" 501 "Agrotronix S.A." 502 "Attwood Corporation" 503 "Naviop S.R.L." 504 "Vesper Marine" 505 "Yetter Farm Equipment" 506 "IHI STAR Machinery Corporation" 507 "Test Center ISOBUS" 508 "Transtech Innovations" 509 "MOTORTECH GmbH" 510 "Marinesoft Co. Ltd" 511 "Sulky" 512 "Inpower LLC" 513 "FarmscanAg" 514 "DISTek Integration, Inc." 515 "GINAF Trucks Nederland B.V." 516 "AVAT Automation GmbH" 517 "Noland Engineering" 518 "Transas USA Inc." 519 "Peeters Landbouwmachines b.v." 520 "Trapeze" ;
VAL_ 2566838526 IndustryGroup 7 "NotAvailable" 5 "Reserved" 4 "Marine" 3 "Construction" 2 "AgriculturalAndForestry" 1 "OnHighway" 0 "Global" ;
VAL_ 2566838526 VehicleSystem1 0 "Non-specific System" 127 "Not Available" 1 "Tractor" 2 "Trailer" ;
VAL_ 2566838526 VehicleSystem2 0 "Non-specific System" 127 "Not Available" 1 "Tractor" 2 "Tillage" 3 "Secondary Tillage" 4 "Planters/Seeders" 5 "Fertilizers" 6 "Sprayers" 7 "Harvesters" 8 "Root Harvesters" 9 "Forage" 10 "Irrigation" 11 "Transport/Trailer" 12 "Farm Yard Operations" 13 "Powered Auxiliary Device" 14 "Special Crops" 15 "Earth Work" 16 "Skidder" 17 "Sensor Systems" 19 "Timber Harvesters" 20 "Forwarders" 21 "Timber loaders" 22 "Timber Processing Machines" 23 "Mulchers" 24 "Utility Vehicles" 25 "Slurry Applicators" ;
VAL_ 2566838526 VehicleSystem3 0 "Non-specific System" 127 "Not Available" 1 "Skid Steer Loader" 2 "Articulated Dump Truck" 3 "Backhoe" 4 "Crawler" 5 "Excavator" 6 "Forklift" 7 "Four Wheel Drive Loader" 8 "Grader" ;
VAL_ 2566838526 VehicleSystem4 0 "Non-specific System" 127 "Not Available" 10 "System Tools" 20 "Safety Systems" 25 "Inter/Intranetwork Device" 30 "Electrical Distribution" 40 "Steering and Control Surfaces" 50 "Propulsion" 60 "Navigation" 70 "Communications" 80 "Instrumentation/General Systems (deprecate)" 90 "Internal Environment" 100 "Deck, Cargo and Fishing Equipment" 35 "Electrical Generation" 75 "Sensor Communication Interface" 85 "External Environment" 120 "Display" 125 "Entertainment" ;
VAL_ 2566838526 VehicleSystem5 0 "Ind. Process Control Stationary" 127 "Not Available" ;
VAL_ 2566838526 VehicleSystem 127 "Not Available" 0 "Non-specific System" ;
VAL_ 2566838526 Function 43 "Transmission Display" 44 "Exhaust Emission Control" 45 "Vehicle Dynamic Stability Control" 46 "Oil Sensor Unit" 47 "Information System Controller" 48 "Ramp Control" 49 "Clutch/Converter Control" 50 "Auxiliary Heater" 51 "Forward-Looking Collision Warning System" 52 "Chassis Controller" 53 "Alternator/Charging System" 54 "Communications Unit, Cellular" 55 "Communications Unit, Satellite" 56 "Communications Unit, Radio" 57 "Steering Column Unit" 58 "Fan Drive Control" 59 "Starter" 60 "Cab Display" 61 "File Server/Printer" 62 "On-Board Diagnostic Unit" 63 "Engine Valve Controller" 64 "Endurance Braking" 65 "Gas Flow Measurement" 66 "I/O Controller" 67 "Electrical System Controller" 68 "Aftertreatment system gas measurement" 69 "Engine Emission Aftertreatement System" 70 "Auxiliary Regeneration Device" 71 "Transfer Case Control" 72 "Coolant Valve Controller" 73 "Rollover Detection Control" 74 "Lubrication System" 75 "Supplemental Fan" 76 "Temperature Sensor" 77 "Fuel Properties Sensor" 78 "Fire Suppression System" 79 "Reserved" 80 "Reserved" 81 "Reserved" 82 "Reserved" 83 "Reserved" 84 "Reserved" 85 "Reserved" 86 "Reserved" 87 "Reserved" 88 "Reserved" 89 "Reserved" 90 "Reserved" 91 "Reserved" 92 "Reserved" 93 "Reserved" 94 "Reserved" 95 "Reserved" 96 "Reserved" 97 "Reserved" 98 "Reserved" 99 "Reserved" 100 "Reserved" 0 "Engine" 1 "Auxiliary Power Unit (APU)" 2 "Electric Propulsion Control" 3 "Transmission" 4 "Battery Pack Monitor" 5 "Shift Control/Console" 6 "Power TakeOff - (Main or Rear)" 7 "Axle - Steering" 8 "Axle - Drive" 9 "Brakes - System Controller" 10 "Brakes - Steer Axle" 11 "Brakes - Drive Axle" 12 "Retarder - Engine" 13 "Retarder - Driveline" 14 "Cruise Control" 15 "Fuel System" 16 "Steering Controller" 17 "Suspension - Steer Axle" 18 "Suspension - Drive Axle" 19 "Instrument Cluster" 20 "Trip Recorder" 21 "Cab Climate Control" 22 "Aerodynamic Control" 23 "Vehicle Navigation" 24 "Vehicle Security" 25 "Network Interconnect ECU" 26 "Body Controller" 27 "Power TakeOff (Secondary or Front)" 28 "Off Vehicle Gateway" 29 "Virtual Terminal (in cab)" 30 "Management Computer" 31 "Propulsion Battery Charger" 32 "Headway Controller" 33 "System Monitor" 34 "Hydraulic Pump Controller" 35 "Suspension - System Controller" 36 "Pneumatic - System Controller" 37 "Cab Controller" 38 "Tire Pressure Control" 39 "Ignition Control Module" 40 "Seat Control" 41 "Lighting - Operator Controls" 42 "Water Pump Control" 101 "Reserved" 102 "Reserved" 103 "Reserved" 104 "Reserved" 105 "Reserved" 106 "Reserved" 107 "Reserved" 108 "Reserved" 109 "Reserved" 110 "Reserved" 111 "Reserved" 112 "Reserved" 113 "Reserved" 114 "Reserved" 115 "Reserved" 116 "Reserved" 117 "Reserved" 118 "Reserved" 119 "Reserved" 120 "Reserved" 121 "Reserved" 122 "Reserved" 123 "Reserved" 124 "Reserved" 125 "Reserved" 126 "Reserved" 127 "Reserved" ;
VAL_ 2566838526 ManufacturerCode 234 "Mondial electronic GmbH" 235 "SailorMade Marine Telemetry - Tetra Technology Ltd." 236 "Norac Systems International Inc" 237 "Agtron Enterprises Inc" 238 "ZF Friedrichshafen AG" 239 "May & Scofield Ltd" 240 "Vanair Mfg" 241 "Schneider Automation SAS " 242 "Kokusandenki Co. Ltd" 243 "eRide, Inc." 244 "Techno-Matic" 245 "Capstan Ag Systems, Inc." 246 "Class 1, Inc" 247 "ePULSE" 248 "Cooper Standard Automotive Active Systems Group" 264 "Autolync" 265 "MTS Sensor Technologie GmbH" 266 "International Thermal Research Ltd" 267 "Red Lion Controls, Inc" 268 "Accurate Technologies" 269 "Saft America Inc.,  Space & Defense Division" 270 "Tennant" 271 "Cole Hersee" 312 "Lectronix, Inc." 313 "Ilmor Engineering, Inc" 314 "CSM GmbH" 315 "Icom Incorporated" 316 "ITT Flow Control" 317 "Navtronics Bvba" 318 "SAT Plan" 319 "Cadec Global" 320 "Miedema Landbouwwerktuigenfabriek B.V." 321 "Ultra Electronics, Electrics" 322 "MICHENKA s.r.o." 323 "Mobileye Vision Technologies Ltd." 324 "Snap-on Diagnostics" 325 "ASM Automation Sensorik Messtechnik GmbH" 326 "Akron Brass Company" 327 "Sonceboz SA" 272 "Gross Mechanical Laboratories, Inc" 273 "Active Research Limited" 274 "LTW Technology Co., LTD" 275 "Navico Egersund AS" 276 "Aqua-Hot Heating Systems" 277 "LHP Telematics" 278 "Takata Electronics" 279 "Geometris LP" 280 "Leica Geosystems Pty Ltd" 299 "Rauch Landmaschinen GmbH" 300 "Systron Donner Automotive" 301 "Parker Hannifin (UK) Ltd FDE group" 302 "Nissin Kogyo Co., LTD" 303 "CTS Corporation" 304 "EmpirBus AB" 305 "NovAtel Inc" 306 "Sleipner Motor AB" 307 "MBW Technologies" 308 "Cyntrx" 309 "Krauss-Maffei Wegmann GmbH & Co. KG" 310 "TECNORD srl" 311 "Patrick Power Products" 281 "Precision Governors LLC" 282 "Medallion Instrumentation Systems" 283 "CWF Hamilton & Co Ltd" 284 "Mobile Tech Chile" 285 "Sea Recovery Corp" 286 "Coelmo srl" 287 "NTech Industries, Inc" 288 "Mitsubishi FUSO Truck & Bus Corp." 289 "Watlow" 290 "Kuebler GmbH" 291 "Groeneveld Transport Efficiency BV" 292 "IKUSI - Angel Iglesias S.A." 293 "Spyder Controls Corp." 294 "Grayhill Inc." 295 "BEP Marine" 296 "micro dynamics GmbH" 297 "Zonar Systems Inc" 298 "Holley Performance" 253 "Mobile Control Systems" 254 "GE Sensing" 255 "MEAS France" 256 "Tyco Electronics AMP" 257 "Honda Motor Co., Ltd" 258 "ARAG" 259 "Jetter AG" 260 "Reichhardt GmbH" 261 "Red Dot Corporation" 262 "HydraForce, Inc" 263 "IMMI" 223 "Vaueo Retarder Co., Ltd." 224 "EMMI Network, S.L." 225 "SKF" 226 "Monaco Coach Corporation" 227 "Lykketronic A/S" 228 "ZF Marine Electronics" 229 "Garmin International Inc." 230 "Saucon Technologies" 231 "Topcon Positioning Systems, Inc." 0 "Reserved" 1 "Allied Signal Inc." 2 "Allison Transmission, GMC" 3 "Ametek, US Gauge Division" 4 "Ametek-Dixson" 5 "AMP Inc." 6 "Berifors Electronics AB" 7 "Case Corp." 8 "Caterpillar Inc." 9 "Chrysler Corp." 10 "Cummins Engine Co." 11 "Dearborn Group Inc." 12 "Deere & Company, Precision Farming" 13 "Delco Electronics" 14 "Detroit Diesel Corporation" 15 "Dickey-John Corp." 16 "Eaton Corp." 17 "Eaton Corp. Res & Dev" 18 "Eaton Corp, Transmission Division" 19 "Eaton Corp. Trucking Info Services" 20 "Eaton Ltd" 21 "Echilin Inc., Midland Brake Inc." 22 "Ford Motor Co., Electronic Concepts $ Systems" 23 "Ford Motor Co., Heavy Truck" 24 "Ford Motor Co., Vehicle Controls" 25 "Daimler Trucks North America LLC" 26 "General Motors Corp., Service Technology Group" 27 "GMC" 28 "Grote Ind. Inc." 29 "Hino Motors Ltd." 30 "Isuzu Motors Ltd." 31 "J Pollak Corp." 32 "Jacobs Vehicle Systems" 33 "John Deere" 34 "Kelsey Hayes Co." 35 "Kenworth Truck Co." 36 "Lucas Ltd." 37 "Mack Trucks Inc." 38 "Micro Processor Systems Inc." 39 "Microfirm Inc." 40 "Motorola AIEG Inc." 41 "Motorola Inc." 42 "International Truck and Engine Corp. Engine Electronics" 43 "International Truck and Engine Corp. Vehicle Electronics" 44 "Nippondenso Co. Ltd." 45 "PACCAR" 46 "Noregon Systems, Inc" 47 "Phillips Semiconductor" 48 "Pollak Alphabet" 49 "RE America Inc." 50 "Robert Bosch Corp" 51 "Robert Bosch GmbH" 52 "Meritor Automotive, Inc." 53 "Continental Automotive Systems US, Inc." 54 "Meritor Wabco" 55 "Ryder System Inc." 56 "SAIC" 57 "Sauer-Danfoss Co." 58 "SPX Corporation, OTC Division" 59 "VES Inc." 60 "Volvo Trucks North America Inc." 61 "Volvo Truck Corp." 62 "Wabco" 63 "ZF Industries Inc." 64 "unused" 65 "MAN Nutzfahrzeuge AG" 66 "John Deere Construction Equipment Division" 67 "Funk Manufacturing Company" 68 "Scania" 69 "Trimble Navigation" 70 "Flex-Coil Limited" 71 "Vansco Electronics Ltd." 72 "Sisu Corporation" 73 "LeTourneau, Inc." 74 "Eaton Axle-Brake Division" 75 "Deere & Co. Agricultural Division" 76 "unused" 77 "Deere Power Systems Group" 78 "Frank W. Murphy Manufacturing, Inc." 79 "Daimler Benz AG - Engine Division (PBM)" 80 "Twin Disc, Inc." 81 "Fire Research Corp" 82 "Bobcat/Ingersoll-Rand" 83 "Bendix VORAD Technologies" 84 "New Holland UK Limited" 85 "Kohler Co." 86 "C.E. Niehoff & Company" 87 "J.C. Bamford Excavators Ltd (JCB)" 88 "Satloc Precision GPS" 89 "Kverneland Group, Electronics Division" 90 "Knorr-Bremse SfN GmbH" 91 "BSG Bodensee Steuergeraete GmbH" 92 "Ag-Chem Equipment Co., Inc." 93 "Perkins Engines Company Ltd." 94 "CNH Global N.V." 95 "Pacific Insight Electronics Corp." 96 "Mech@tronic IT GmbH" 97 "Ag Leader Technology, Inc." 98 "Mueller-Elektronik GmbH & Co." 99 "International Transmissions Ltd (ITL)" 100 "VDO Technik AG" 101 "Sensoria" 102 "AGCO GmbH & Co." 103 "CLAAS Agrosystems GmbH & Co. KG" 104 "Claas Selbstfahrende Erntemaschinen GmbH" 105 "Kiepe Elektrik GmbH & Co. KG" 106 "BAE Systems Controls, Inc." 107 "Grimme Landmaschinen GmbH & Co. KG" 108 "WTK-Elecktronik GmbH" 109 "TeeJet Technologies Denmark" 110 "EPIQ Sensor-Nite" 111 "Maschinenfabrik Bernard Krone GmbH" 112 "MECALAC" 113 "Stress-Tek, Inc." 114 "EControls, Inc." 115 "NACCO Materials Handling Group, Inc." 116 "BEELINE Technologies" 117 "HUSCO International" 118 "Intron GmbH" 119 "IntegriNautics" 120 "RDS Technology Ltd." 121 "HED (Hydro Electronic Devices, Inc.)" 122 "FG Wilson (Engineering) Limited" 123 "Basler Electric" 124 "Hydac Electronic" 125 "Nevada Automotive Test Center" 126 "Driver Tech" 127 "Holland USA" 128 "Gerhard Duecker GmbH & Co. KG" 129 "OMNEX Control Systems, Inc." 130 "Nido - Universal Machines B.V." 131 "ITT Industries" 132 "Mulag-Fahrzeugwerk" 133 "Bucher Schoerling GmbH" 134 "Iris Technology Ltd." 135 "Airmar Technology Corporation" 136 "Komatsu Ltd." 137 "Maretron" 138 "Georg Fritzmeier GmbH & Co. KG" 139 "Caterpillar Trimble Control Technologies (CTCT), LLC" 140 "Lowrance Electronics, Inc." 141 "Thales Navigation Ltd." 142 "TRW Automotive (Commercial Steering Systems)" 143 "W. Gmeiner GmbH & Co." 144 "Mercury Marine" 145 "MurCal Controls" 146 "Maxima Technologies" 147 "Nautibus Electronic GmbH" 148 "Blue Water Data, Inc." 149 "Holset" 150 "Fleetguard" 151 "Raven Industries Inc. - Flow Controls Division" 152 "elobau GmbH & Co. KG" 153 "Woodward, Industrial Controls Division" 154 "Westerbeke Corporation" 155 "Vetronix Corporation" 156 "ITT Industries - Cannon" 157 "ISSPRO Inc." 158 "Firestone Industrial Products Company" 159 "NTech Industries Inc." 160 "Nido" 161 "Offshore Systems (UK) Limited" 162 "Axiomatic Technologies" 163 "BRP Inc." 164 "DaimlerChrysler Off-Highway" 165 "CPAC Systems AB" 166 "Phoenix International" 167 "JLG Industries Inc." 168 "Xantrex" 169 "Marlin Technologies Inc." 170 "Computronics Corporation Ltd." 171 "Wachendorff Elektronik GmbH & Co. KG" 172 "Yanmar Marine USA" 173 "Ryeso, Inc." 174 "AB Volvo Penta" 175 "Veris Technologies, Inc." 176 "Moritz Aerospace" 177 "Diagnostic System Associates" 178 "Siemens VDO Automotive AG" 179 "TeeJet Technologies Denmark" 180 "Smart Power Systems" 181 "Coretronics, Inc." 182 "Vehicle Systems Engineering B.V." 183 "KDS Controls, Inc." 184 "EIA Electronics" 185 "Beede Electrical Instrument Company" 186 "Altronic, Inc." 187 "Air-Weigh" 188 "EMP Corp." 189 "QUALCOMM" 190 "Hella KGaA Hueck & Co." 191 "XRS Corporation" 192 "Floscan" 193 "Nobletec" 194 "TriMark Corporation" 195 "General Engine Products" 196 "LEMKEN GmbH & Co. KG" 197 "Mechron Power Systems" 198 "Mystic Valley Communications" 199 "Actia Corp." 200 "MGM Brakes" 201 "Disenos y Tecnologia S.A." 202 "Curtis Instruments, Inc." 203 "MILtronik GmbH" 204 "The Morey Corporation" 205 "SmarTire Systems Inc" 206 "port GmbH" 207 "Otto Engineering" 208 "Drew Technologies, Inc." 209 "Bell Equip. Co. SA (PTY) LTD" 210 "Iteris, Inc." 211 "DNA Group" 212 "Sure Power Industries, Inc." 213 "CNH Belgium N.V." 214 "MC elettronica Srl" 215 "Aetna Engineering/Fireboy-Xintex" 216 "Paneltronics Inc." 217 "RM Michaelides Software & Elektronik GmbH" 218 "Gits Manufacturing Company" 219 "Cat OEM Solutions" 220 "Beede Electrical Instrument Company, Inc." 221 "SiE" 222 "Generac Power Systems, Inc." 1850 "Teleflex" 1851 "Raymarine" 1852 "Navionics" 1853 "Japan Radio Co." 1854 "Northstar Technologies" 1855 "Furuno USA" 1856 "Trimble" 1857 "Simrad" 1858 "Litton" 1859 "Kvasar AB" 1860 "MMP" 1861 "Vector CANtech" 1862 "Sanshin" 1863 "Thomas G. Faria Co." 232 "TSD Integrated Controls" 233 "Yacht Monitoring Solutions Inc." 249 "Schaltbau GmbH" 250 "Kuhn Group" 251 "German Agricultural Society" 252 "Sensor-Technik Wiedemann GmbH" 328 "Qwerty Electronik AB" 329 "Deif A/S" 330 "Kidde Aerospace and Defense" 331 "Horton, Inc." 332 "HWH Corporation" 333 "Hadley Products Corporation" 334 "Takata-Petri AG" 335 "Evo Electric Ltd" 336 "APE s.r.o." 337 "Carraro S.p.A." 338 "GRAF-SYTECO" 339 "Competence Center ISOBUS e.V." 340 "Continental AG" 341 "Boning GmbH & Co" 342 "THOMAS MAGNETE GmbH" 343 "Baumer Group" 344 "Parvus Corporation" 345 "Korean Maritime University" 346 "Control Solutions" 347 "Honeywell" 348 "Amazonen Werke H. Dreyer" 349 "Suonentiet" 350 "Noris Marine Systems GmbH & Co KG" 351 "Thrane & Thrane" 352 "SAME DEUTZ-FAHR" 353 "Hegemon Electronics, Inc." 354 "Junkkari OY" 355 "Mastervolt International B.V." 356 "Fischer Panda Generators, Inc" 357 "Hardi International A/S" 358 "Victron Energy BV" 359 "Ludwig Bergmann GmbH" 360 "HJS Emission Technology GmbH & Co KG" 361 "InMach" 362 "Alois Poettinger Maschinenfabrik GmbH" 363 "BEI Duncan" 364 "OEM Controls Inc." 365 "Digi-Star, LLC" 366 "Viewnyx Corp." 367 "Fliegl Agrartechnik" 368 "HANSENHOF_electronic" 369 "Power Torque Engineering Ltd" 370 "Rolls-Royce Marine AS" 371 "Heinzmann GmbH & Co. KG" 373 "Electronic Design Inc." 374 "Northern Lights, Inc." 381 "B&G" 372 "Delphi" 375 "Williams Controls Inc." 376 "Quake Global" 377 "ifm electronic gmbh" 378 "Glendinning Marine Products" 379 "Yamabiko Corporation" 380 "Suntech International Ltd." 382 "National Agricultural and Food Research Organization" 383 "MCL Industries" 384 "Camano Light" 385 "Johnson Outdoor Marine Electronics" 386 "JLG Automation BVBA" 387 "Orscheln Products, LLC" 388 "Innomatix, LLC" 389 "Benchmark Electronics, Minnesota Division" 390 "Partech Inc." 391 "Electronic Design for Industry, Inc" 392 "Tianyuan Technology Co Ltd." 393 "Harvest Tec, Inc" 394 "Capi 2 Nederland BV" 395 "GENTEC S.R.L." 396 "Beyond Measure" 397 "Sanyo-kiki Co Ltd." 398 "Hilite International" 399 "ISEKI & Co., Ltd." 400 "Livorsi Marine" 401 "Torqeedo GmbH" 402 "Simma Software, Inc." 403 "Trackwell ADS, Inc." 404 "Com Nav Marine Ltd" 405 "Wema System AS" 406 "Vecima Networks Inc." 407 "Comtech Mobile Datacom" 408 "Corvus Energy Ltd." 409 "Transfluid S.r.L." 410 "COBO S.p.A. Divisione 3B6" 411 "Hy-Drive Technologies Ltd." 412 "WebTech Wireless Inc." 413 "Datapross Nijbroek bv" 414 "Cattron Group International" 415 "Valid Manufacturing Ltd." 416 "Kubota Corporation" 417 "KZValve" 418 "Intellistick Inc" 419 "Fusion Electronics Ltd" 420 "Vermeer Corporation, ACS Group" 421 "Vertex Standard Co., Ltd" 422 "True Heading AB" 423 "BSM Wireless, Inc." 424 "Odyne LLC" 425 "Methode Electronics Inc, MDI" 426 "Egersund Marine Electronics AS" 427 "em-trak Marine Electronics Ltd" 428 "Mfg_428" 429 "Rota Engineering Ltd." 455 "ADZ NAGANO GmbH" 456 "General Kinetics" 457 "RUSELPROM-ElectricDrive Ltd" 458 "Control Solutions, Inc." 459 "Alltek Marine Electronics Corp" 460 "San Giorgio S.E.I.N." 461 "HAWE Hydraulik SE" 462 "IHI Shibaura Machinery Corporation" 463 "PROBOTIQ" 464 "Leach International Corporation" 465 "Ashcroft Inc" 466 "Veethree Electronics and Marine LLC" 467 "Lely Industries N.V." 468 "Tyco Fire Protection Products" 469 "RA Consulting GmbH" 470 "SI-TEX Marine Electronics" 471 "Sea Cross Marine AB" 472 "Tenneco Inc." 473 "Boss Industries, Inc." 474 "Persen Technologies Inc." 475 "GME" 476 "Hummingbird Marine Electronics" 477 "OilQuick AB" 478 "OceanSat BV" 479 "Vapor Bus International" 430 "Auteq Telematica S.A." 431 "Tohatsu Corporation" 432 "S&A Systems, Inc." 433 "Rowe Electronics" 434 "Stored Energy Systems" 435 "Zunhammer GmbH" 436 "Kinze Manufacturing" 437 "Digital Yacht Limited" 438 "Comar Systems Ltd" 439 "Hyundai Heavy Industries" 440 "Cummins Power Generation" 441 "PTG Reifendruckregelsysteme GmbH" 442 "Horsch Maschinen GmbH" 443 "SignalQuest, Inc." 444 "ITT Power Solutions" 445 "KAT MECHATRONIC, Electronic Product Division" 446 "CertTech, L.L.C." 447 "Great Plains Mfg." 448 "Stanadyne Corporation, Electronics Systems" 449 "Polaris Industries Inc" 450 "Dycor Technologies Ltd." 451 "Parker Hannifin Corp" 452 "WIKA Alexander Wiegand SE & Co. KG" 453 "Cooper Bussmann" 454 "NGK Spark Plug Co. Ltd" 480 "EnerDel, Inc." 481 "Chetco Digital Instruments" 482 "Tricon Electronics" 483 "Valeo" 484 "Headsight Inc." 485 "MATT automotive" 486 "Westport Innovations Inc." 487 "DSE Test Solutions A/S" 488 "The Charles Machine Works, Inc." 489 "Appareo Systems" 490 "QuikQ" 491 "Penny and Giles Ltd" 492 "Inergy Automotive Systems" 493 "Watcheye" 494 "Synerject" 495 "HOLMER Maschinenbau GmbH" 496 "W. Gessmann GmbH" 497 "SENTRON Sistemas Embarcados" 498 "Innovative Design Solutions, Inc." 499 "LCJ Capteurs" 500 "Oxbo International Corporation" 501 "Agrotronix S.A." 502 "Attwood Corporation" 503 "Naviop S.R.L." 504 "Vesper Marine" 505 "Yetter Farm Equipment" 506 "IHI STAR Machinery Corporation" 507 "Test Center ISOBUS" 508 "Transtech Innovations" 509 "MOTORTECH GmbH" 510 "Marinesoft Co. Ltd" 511 "Sulky" 512 "Inpower LLC" 513 "FarmscanAg" 514 "DISTek Integration, Inc." 515 "GINAF Trucks Nederland B.V." 516 "AVAT Automation GmbH" 517 "Noland Engineering" 518 "Transas USA Inc." 519 "Peeters Landbouwmachines b.v." 520 "Trapeze" ;
VAL_ 2566734590 CertLaboratoryType_FirstDef 7 "Not available (not certified) " 0 "Non-certified laboratory/self-test" 1 "AEF certified laboratory " 2 "Reserved " ;
VAL_ 2566734590 MessageRevision 1 "Third and later edition message revision" 0 "Format of message in second edition." ;
VAL_ 2566734590 CertificationReferenceNumber 0 "NotCertified" 1 "CertificationTestPerformed" ;
VAL_ 2566734590 CertTypeTaskController 0 "NotCertified" 1 "CertificationTestPerformed" ;
VAL_ 2566734590 CertTypeTCWorkingSetMaster 0 "NotCertified" 1 "CertificationTestPerformed" ;
VAL_ 2566734590 CertTypeTCWorkingSetMember 0 "NotCertified" 1 "CertificationTestPerformed" ;
VAL_ 2566734590 CertTypeFileServer 0 "NotCertified" 1 "CertificationTestPerformed" ;
VAL_ 2566734590 CertTypeGPSReceiver 0 "NotCertified" 1 "CertificationTestPerformed" ;
VAL_ 2566734590 CertTypeMinimumECU 0 "NotCertified" 1 "CertificationTestPerformed" ;
VAL_ 2566734590 CertTypeTECUClass1 0 "NotCertified" 1 "CertificationTestPerformed" ;
VAL_ 2566734590 CertTypeTECUClass2 0 "NotCertified" 1 "CertificationTestPerformed" ;
VAL_ 2566734590 CertTypeTECUClass3 0 "NotCertified" 1 "CertificationTestPerformed" ;
VAL_ 2566734590 CertTypeClass3ECU 0 "NotCertified" 1 "CertificationTestPerformed" ;
VAL_ 2566734590 CertTypeVirtualTerminal 0 "NotCertified" 1 "CertificationTestPerformed" ;
VAL_ 2566734590 CertTypeVTWorkingSetMaster 0 "NotCertified" 1 "CertificationTestPerformed" ;
VAL_ 2566734590 CertTypeVTWorkingSetMember 0 "NotCertified" 1 "CertificationTestPerformed" ;
VAL_ 2566734590 CertLaboratoryType_SecondDef 3 "Not available (not certified) " 0 "Non-certified Laboratory/self-certification" 1 "AEF certified laboratory " 2 "Reserved " ;
VAL_ 2566734590 TestProtocolRevision 0 "FirstRevision" 1 "SecondRevision" 2 "ThirdRevision" 3 "NotAvailable" ;
VAL_ 2365408254 MachineSelDirectionCommand 0 "Reverse" 1 "Forward" 2 "Reserved" 3 "DontCare" ;
VAL_ 2364547838 MachineSelectedSpeedLimitStatus 0 "NotLimited" 1 "OperatorLimited_Controlled" 2 "LimitedHigh" 3 "LimitedLow" 4 "Reserved" 5 "Reserved" 6 "NonRecoverableFault" 7 "NotAvailable" ;
VAL_ 2364547838 MachineSelectedSpeedSource 0 "WheelBasedSpeed" 1 "GroundBasedSpeed" 2 "NavigationBasedSpeed" 3 "BlendedSpeed" 4 "SimulatedSpeed" 5 "Reserved" 6 "Reserved" 7 "NotAvailable" ;
VAL_ 2364547838 MachineSelectedDirection 0 "Reverse" 1 "Forward" 2 "ErrorIndication" 3 "NotAvailable" ;
VAL_ 2365391616 ImplementOperatingStateCmd 0 "SetImplementToFieldWorkingState" 1 "SetImplementToTransportState" 2 "SetImplementToParkState" 3 "TakeNoAction" ;
VAL_ 2365391360 StopAllImplementOperations 0 "StopImplementOperations" 1 "PermitAllImplementsToON " 2 "ErrorIndication" 3 "NotAvailable " ;
VAL_ 2314732286 COGReference 0 "True" 1 "Magnetic" 2 "Error" 3 "Null" ;
VAL_ 2314732286 SID 255 "nVldPsFxTTItTRng0T250FrVldPstnFx" ;
VAL_ 2358181630 BusyFlagParsing 0 "NotBusy" 1 "SCMIsParsingAnSCD" ;
VAL_ 2358181630 BusyFlagMemoryAccess 0 "NotBusy" 1 "BusyWithNonVolatileMemoryAccess" ;
VAL_ 2358181630 ExecutionIndicationResponseError 0 "NoError" 1 "FunctionIDNotDefined" 2 "StateIDNotDefined" 3 "FunctionExecutionStateMismatch" 4 "SCMOutOfMemory" 5 "PlayBackContinues" 6 "PlayBackHaltedDueToOperator" 255 "GeneralError" ;
VAL_ 2358181630 SequenceState 1 "Ready" 2 "Recording" 3 "RecordingCompletition" 4 "PlayBack" 5 "Abort" 255 "SequenceStateNotAvailable" ;
VAL_ 2358181630 ReasonIndicator 1 "StatusChangeOnOperatorCommand" 2 "SCCNotPartOfSelectedSCS" 3 "SCCIsPartOfSelectedSCS" 255 "NoSpecificReason" ;
VAL_ 2358181630 FunctionExecutionState 0 "FunctionExecStartedAndCompleted" 1 "FunctionExecutionStarted" 2 "FunctionExecutionCompleted" 3 "ErrorDuringExecution" ;
VAL_ 2358181630 FunctionExecutionStateAck 0 "AckOfFuncExecStartAndCompletion" 1 "AckOfFunctionExecutionStarted" 2 "AckOfFunctionExecutionCompleted" 3 "AckErrorDuringExecution" ;
VAL_ 2358181630 SequenceNumber 255 "NoSequenceAvailable" ;
VAL_ 2358181630 MemoryStatus 0 "EnoughMemoryAvailable" 1 "NotEnoughMemoryAvailable" ;
VAL_ 2358181630 VersionResponseError 0 "NoError" 1 "NoMatchingSCDStored" 255 "GeneralError" ;
VAL_ 2358181630 ConfigLabelResponseError 0 "NoError" 1 "NoMatchingSCDStored" 255 "GeneralError" ;
VAL_ 2358181630 TransferResponseError 0 "NoError" 1 "ErrorOccurredDuringTransfer" 255 "GeneralError" ;
VAL_ 2358181630 ActivationResponseError 0 "NoError" 1 "UnknownObjectType" 2 "BasicObjectDoesNotExist" 3 "ReferencedFunctObjDoesNotExist" 4 "ReferencedStateObjDoesNotExist" 5 "ReferencedStringObjDoesNotExist" 6 "ReferencedGraphObjDoesNotExist" 7 "ObjectIDIsNotUnique" 8 "FunctionIDIsNotUnique" 9 "StateIDIsNotUnique" 10 "DesignatorStringthLengthIsZero" 11 "InvalidGraphicObject" 12 "SCDVersionLabelLengthIncorrect" 13 "SCDConfigLabelLengthIncorrect" 14 "SCVersionNotSupportedBySCM" 255 "GeneralError" ;
VAL_ 2358181630 SCMState 0 "Inactive" 1 "Active" 2 "Initialization" ;
VAL_ 2358181630 SCVersion 0 "DIS" 1 "FDIS" 2 "IS" ;
VAL_ 2358181630 CommandedSCCState 0 "Disabled" 1 "Enabled" ;
VAL_ 2358181630 DeleteCommandResponseError 0 "NoError" 1 "SCDDoesNotExist" 255 "GeneralError" ;
VAL_ 2358181630 StoreCommandError 0 "NoError" 1 "SCDWasNotCompletelyParsed" 2 "NotEnoughNonVolatileMemory" 255 "GeneralError" ;
VAL_ 2358181630 LoadResponseError 0 "NoError" 1 "SCDNotFound" 2 "FileSystemErrorOrDataCorruption" 3 "NotEnoughVolatileMemoryAvailable" 255 "GeneralError" ;
VAL_ 2358181630 MessageCode 1 "SCDVersionResponse" 2 "SCDConfigurationLabelResponse" 3 "SCDTransferResponse" 4 "SCDActivationResponse" 5 "SCDDeleteResponse" 6 "SCDStoreResponse" 7 "SCDLoadResponse" 48 "SCStateCommand" 50 "SCExecutionIndicationResponse" 51 "SCMasterExecutionCommand" 52 "SCClientExecutionAcknowledgement" 53 "SCClientFunctionErrorRequest" 144 "SCMasterCapablilityResponse" 145 "SCMasterMemoryResponse" 149 "SCMasterStatus" ;
VAL_ 2358116094 OperatorConfirmationRequired3 0 "no" 1 "yes" ;
VAL_ 2358116094 ClientFunctionErrorStatuts3 1 "OneTimeError" 2 "PermanentError" 3 "ClientFunctionIsLocked" 4 "ClientFunctionIsDeactivated" 15 "GeneralError" ;
VAL_ 2358116094 OperatorConfirmationRequired2 0 "no" 1 "yes" ;
VAL_ 2358116094 ClientFunctionErrorStatuts2 1 "OneTimeError" 2 "PermanentError" 3 "ClientFunctionIsLocked" 4 "ClientFunctionIsDeactivated" 15 "GeneralError" ;
VAL_ 2358116094 ClientFunctonErrorState 0 "NoError" 1 "ErrorStateNotChanged" 2 "ErrorStateChanged" 3 "ErrorStateReqConfirmationChanged" 255 "ErrorStateNotAvailable" ;
VAL_ 2358116094 OperatorConfirmationRequired1 0 "no" 1 "yes" ;
VAL_ 2358116094 ClientExecutionError 0 "NoError" 1 "ErrorInTheFunction" 2 "OperatorInteraction" 3 "ConditionsOfSCCAllowNoExecution" 255 "GeneralError" ;
VAL_ 2358116094 ClientFunctionErrorStatuts1 1 "OneTimeError" 2 "PermanentError" 3 "ClientFunctionIsLocked" 4 "ClientFunctionIsDeactivated" 15 "GeneralError" ;
VAL_ 2358116094 ClientAbortError 1 "TimeoutOnStatusMessage" 2 "OperatorInteraction" 3 "ErrorDuringFunctionExecution" 255 "GeneralError" ;
VAL_ 2358116094 SequenceState 1 "Ready" 2 "Recording" 4 "PlayBack" 5 "Abort" 255 "SequenceStateNotAvailable" ;
VAL_ 2358116094 FunctionExecutionState 0 "FunctionExecStartedAndCompleted" 1 "FunctionExecutionStarted" 2 "FunctionExecutionCompleted" 3 "ErrorDuringExecution" ;
VAL_ 2358116094 NewFunctionExecutionState 0 "FunctionExecStartedAndCompleted" 1 "FunctionExecutionStarted" 2 "FunctionExecutionCompleted" 3 "ErrorDuringExecution" ;
VAL_ 2358116094 SequenceNumber 255 "NoSequenceAvailable" ;
VAL_ 2358116094 SCCState 0 "Disabled" 1 "Enabled" 2 "Initialization" ;
VAL_ 2358116094 DeleteCommandType 0 "DeleteSCDInVolatileMemory" 1 "DeleteSCDInNonVolatileMemory" ;
VAL_ 2358116094 MessageCode 1 "SCDVersionRequest" 2 "SCDConfigurationLabelRequest" 3 "SCDTransfer" 4 "SCDActivationCommand" 5 "SCDDeleteCommand" 6 "SCDStoreCommand" 7 "SCDLoadCommand" 49 "SCClientAbort" 50 "SCExecutionIndication" 52 "SCClientExecutionStatus" 53 "SCClientFunctionErrorResponse" 144 "SCMasterCapabilityRequest" 145 "SCMasterMemoryRequest" 150 "SCClientStatus" ;
VAL_ 2559835902 NMControlModeIndicator 0 "SetPendingName" 1 "PendingName" 2 "CurrentName" 3 "NameACK" 4 "NameNACK" 5 "ReqPendingName" 6 "ReqCurrentName" 7 "AdoptPendingName" 8 "ReqNameAddressClaim" ;
VAL_ 2559835902 ErrorCode 0 "Security not satisfied" 1 "Item(s) not allowed to change" 2 "Item conflict" 3 "Checksum does not match" 4 "Pending Name not set" 255 "Not Available" 5 "Other" ;
VAL_ 2566704384 DriveStrategyExitReason 0 "No reason/all clear " 1 "Operator presence not detected " 2 "Implement released control of function " 3 "Operator override of function " 4 "Operator control not in valid position" 5 "Remote command timeout" 6 "Remote command out of range/invalid " 7 "Function not calibrated " 8 "Operator control fault" 9 "Function fault " 22 "Vehicle transmission gear does not allow remote commands" 62 "Error " 63 "Not available (parameter not supported) " ;
VAL_ 2566704384 DriveStrategyPriority1 0 "Enable maximum draft power control " 1 "Enable constant PTO speed control" 2 "Enable wheel speed/PTO speed ratio control" 3 "Enable minimum engine speed control" 4 "Enable engine economy control " 5 "Enable maximum hydraulic power control" 6 "Enable maximum electric power control" 253 "Requested mode not supported " 254 "Error or reserved" 255 "Not available/Don't care " ;
VAL_ 2566704384 DriveStrategyPriority2 0 "Enable maximum draft power control " 1 "Enable constant PTO speed control" 2 "Enable wheel speed/PTO speed ratio control" 3 "Enable minimum engine speed control" 4 "Enable engine economy control " 5 "Enable maximum hydraulic power control" 6 "Enable maximum electric power control" 253 "Requested mode not supported " 254 "Error or reserved" 255 "Not available/Don't care " ;
VAL_ 2566704384 DriveStrategyPriority3 0 "Enable maximum draft power control " 1 "Enable constant PTO speed control" 2 "Enable wheel speed/PTO speed ratio control" 3 "Enable minimum engine speed control" 4 "Enable engine economy control " 5 "Enable maximum hydraulic power control" 6 "Enable maximum electric power control" 253 "Requested mode not supported " 254 "Error or reserved" 255 "Not available/Don't care " ;
VAL_ 2566704384 DriveStrategyPriority4 0 "Enable maximum draft power control " 1 "Enable constant PTO speed control" 2 "Enable wheel speed/PTO speed ratio control" 3 "Enable minimum engine speed control" 4 "Enable engine economy control " 5 "Enable maximum hydraulic power control" 6 "Enable maximum electric power control" 253 "Requested mode not supported " 254 "Error or reserved" 255 "Not available/Don't care " ;
VAL_ 2566704384 DriveStrategyRequestState 0 "External Request Accepted. No subsequent operator intervention" 1 "Control override (most recent external request ignored)" 2 "Error indication " 3 "Not available/Not Installed " ;
VAL_ 2365378048 DriveStrategyPriority1Req 0 "Enable maximum draft power control " 1 "Enable constant PTO speed control" 2 "Enable wheel speed/PTO speed ratio control" 3 "Enable minimum engine speed control" 4 "Enable engine economy control " 5 "Enable maximum hydraulic power control" 6 "Enable maximum electric power control" 254 "Error or reserved" 255 "Not available/Don't care " ;
VAL_ 2365378048 DriveStrategyPriority2Req 0 "Enable maximum draft power control " 1 "Enable constant PTO speed control" 2 "Enable wheel speed/PTO speed ratio control" 3 "Enable minimum engine speed control" 4 "Enable engine economy control " 5 "Enable maximum hydraulic power control" 6 "Enable maximum electric power control" 254 "Error or reserved" 255 "Not available/Don't care " ;
VAL_ 2365378048 DriveStrategyPriority3Req 0 "Enable maximum draft power control " 1 "Enable constant PTO speed control" 2 "Enable wheel speed/PTO speed ratio control" 3 "Enable minimum engine speed control" 4 "Enable engine economy control " 5 "Enable maximum hydraulic power control" 6 "Enable maximum electric power control" 254 "Error or reserved" 255 "Not available/Don't care " ;
VAL_ 2365378048 DriveStrategyPriority4Req 0 "Enable maximum draft power control " 1 "Enable constant PTO speed control" 2 "Enable wheel speed/PTO speed ratio control" 3 "Enable minimum engine speed control" 4 "Enable engine economy control " 5 "Enable maximum hydraulic power control" 6 "Enable maximum electric power control" 254 "Error or reserved" 255 "Not available/Don't care " ;
VAL_ 2365378048 RestoreOpDriveStratSetReq 0 "No Request (sent when implement does not want setting restored) " 1 "Restore Operator Drive Strategy Setting " 2 "Error indication " 3 "Not available " ;
VAL_ 2566688510 Functionality 0 "Minimum control function  " 1 "Universal terminal (server)" 2 "Universal terminal working set (client) " 3 "Aux-O inputs " 4 "Aux-O functions " 5 "Aux-N inputs " 6 "Aux-N functions " 7 "Task controller basic (server) " 8 "Task controller basic working set (client)" 9 "Task controller geo (server) " 10 "Task controller geo working set (client) " 11 "Task controller section control (server) " 12 "Task controller section control working set (client)" 13 "Basic Tractor ECU (server) " 14 "Basic Tractor ECU implement set (client) " ;
SG_MUL_VAL_ 2565734142 FailureReasonCode ControlByte 194-195;
SG_MUL_VAL_ 2565734142 Status ControlByte 194-195;
SG_MUL_VAL_ 2565734142 NameOfCF ControlByte 192-193;
SG_MUL_VAL_ 2565734142 NIECUPort ControlByte 64-67;
SG_MUL_VAL_ 2565734142 FilterMode ControlByte 1-1, 6-6, 7-7;
SG_MUL_VAL_ 2565734142 FromPort ControlByte 0-4, 6-7, 131-131, 132-132, 133-133, 192-195;
SG_MUL_VAL_ 2565734142 ToPort ControlByte 0-4, 6-7, 131-131, 132-132, 133-133, 192-195;
SG_MUL_VAL_ 2358181630 MaxDesignatorStringLength MessageCode 144-144;
SG_MUL_VAL_ 2358181630 BusyFlagParsing MessageCode 149-149;
SG_MUL_VAL_ 2358181630 ReceivedTAN MessageCode 50-50;
SG_MUL_VAL_ 2358181630 RecordedFunctionValue MessageCode 51-51;
SG_MUL_VAL_ 2358181630 BusyFlagMemoryAccess MessageCode 149-149;
SG_MUL_VAL_ 2358181630 ExecutionIndicationResponseError MessageCode 50-50;
SG_MUL_VAL_ 2358181630 TAN MessageCode 51-51, 52-52;
SG_MUL_VAL_ 2358181630 SequenceState MessageCode 149-149;
SG_MUL_VAL_ 2358181630 ReasonIndicator MessageCode 48-48;
SG_MUL_VAL_ 2358181630 GraphicsHeight MessageCode 144-144;
SG_MUL_VAL_ 2358181630 FunctionExecutionState MessageCode 50-50;
SG_MUL_VAL_ 2358181630 FunctionExecutionStateAck MessageCode 52-52;
SG_MUL_VAL_ 2358181630 StateID MessageCode 50-50, 52-52;
SG_MUL_VAL_ 2358181630 ActualConfigurationLabel ConfigLabelResponseError 0-0;
SG_MUL_VAL_ 2358181630 ActualVersionLabel VersionResponseError 0-0;
SG_MUL_VAL_ 2358181630 GraphicsWidth MessageCode 144-144;
SG_MUL_VAL_ 2358181630 RecordedStateID MessageCode 51-51;
SG_MUL_VAL_ 2358181630 SequenceNumber MessageCode 149-149;
SG_MUL_VAL_ 2358181630 ObjectIdOfFirstFaultyObject MessageCode 4-4;
SG_MUL_VAL_ 2358181630 RecordedFunctionID MessageCode 51-51, 52-52;
SG_MUL_VAL_ 2358181630 MemoryStatus MessageCode 145-145;
SG_MUL_VAL_ 2358181630 VersionResponseError MessageCode 1-1;
SG_MUL_VAL_ 2358181630 ConfigLabelResponseError MessageCode 2-2;
SG_MUL_VAL_ 2358181630 TransferResponseError MessageCode 3-3;
SG_MUL_VAL_ 2358181630 ActivationResponseError MessageCode 4-4;
SG_MUL_VAL_ 2358181630 SCMState MessageCode 149-149;
SG_MUL_VAL_ 2358181630 FunctionID MessageCode 50-50;
SG_MUL_VAL_ 2358181630 SCVersion MessageCode 144-144;
SG_MUL_VAL_ 2358181630 CommandedSCCState MessageCode 48-48;
SG_MUL_VAL_ 2358181630 DeleteCommandResponseError MessageCode 5-5;
SG_MUL_VAL_ 2358181630 StoreCommandError MessageCode 6-6;
SG_MUL_VAL_ 2358181630 LoadResponseError MessageCode 7-7;
SG_MUL_VAL_ 2358116094 OperatorConfirmationRequired3 NumberOfFaultyFunctions 3-255;
SG_MUL_VAL_ 2358116094 ClientFunctionErrorStatuts3 NumberOfFaultyFunctions 3-255;
SG_MUL_VAL_ 2358116094 IDOfFaultyClientFunction3 NumberOfFaultyFunctions 3-255;
SG_MUL_VAL_ 2358116094 OperatorConfirmationRequired2 NumberOfFaultyFunctions 2-255;
SG_MUL_VAL_ 2358116094 ClientFunctionErrorStatuts2 NumberOfFaultyFunctions 2-255;
SG_MUL_VAL_ 2358116094 ReceivedTAN MessageCode 52-52;
SG_MUL_VAL_ 2358116094 FunctionValue FunctionExecutionState 0-0, 2-2;
SG_MUL_VAL_ 2358116094 IDOfFaultyClientFunction2 NumberOfFaultyFunctions 2-255;
SG_MUL_VAL_ 2358116094 ClientFunctonErrorState MessageCode 150-150;
SG_MUL_VAL_ 2358116094 OperatorConfirmationRequired1 NumberOfFaultyFunctions 1-255;
SG_MUL_VAL_ 2358116094 TAN MessageCode 50-50;
SG_MUL_VAL_ 2358116094 ClientExecutionError MessageCode 52-52;
SG_MUL_VAL_ 2358116094 ClientFunctionErrorStatuts1 NumberOfFaultyFunctions 1-255;
SG_MUL_VAL_ 2358116094 ClientAbortError MessageCode 49-49;
SG_MUL_VAL_ 2358116094 SequenceState MessageCode 150-150;
SG_MUL_VAL_ 2358116094 FunctionExecutionState MessageCode 50-50;
SG_MUL_VAL_ 2358116094 NewFunctionExecutionState MessageCode 52-52;
SG_MUL_VAL_ 2358116094 NewStateID MessageCode 52-52;
SG_MUL_VAL_ 2358116094 IDOfFaultyClientFunction1 NumberOfFaultyFunctions 1-255;
SG_MUL_VAL_ 2358116094 StateID MessageCode 50-50;
SG_MUL_VAL_ 2358116094 SequenceNumber MessageCode 150-150;
SG_MUL_VAL_ 2358116094 NumberOfFaultyFunctions MessageCode 53-53;
SG_MUL_VAL_ 2358116094 RecordedFunctionID MessageCode 52-52;
SG_MUL_VAL_ 2358116094 SCCState MessageCode 150-150;
SG_MUL_VAL_ 2358116094 FunctionID MessageCode 50-50;
SG_MUL_VAL_ 2358116094 MemoryRequired MessageCode 145-145;
SG_MUL_VAL_ 2358116094 AddressSCCWSM MessageCode 4-4;
SG_MUL_VAL_ 2358116094 DeleteCommandType MessageCode 5-5;
SG_MUL_VAL_ 2559835902 ManufacturerCodeQualifierFlag NMControlModeIndicator 0-0, 4-4, 8-8;
SG_MUL_VAL_ 2559835902 ECUInstanceQualifierFlag NMControlModeIndicator 0-0, 4-4, 8-8;
SG_MUL_VAL_ 2559835902 FunctionInstanceQualifierFlag NMControlModeIndicator 0-0, 4-4, 8-8;
SG_MUL_VAL_ 2559835902 FunctionQualifierFlag NMControlModeIndicator 0-0, 4-4, 8-8;
SG_MUL_VAL_ 2559835902 VehicleSystemQualifierFlag NMControlModeIndicator 0-0, 4-4, 8-8;
SG_MUL_VAL_ 2559835902 VehicleSystemInstanceQualifierFl NMControlModeIndicator 0-0, 4-4, 8-8;
SG_MUL_VAL_ 2559835902 IndustryGroupQualifierFlag NMControlModeIndicator 0-0, 4-4, 8-8;
SG_MUL_VAL_ 2559835902 ArbitraryAddressCapableQualifier NMControlModeIndicator 0-0, 4-4, 8-8;
SG_MUL_VAL_ 2559835902 CommandManufacturerCode NMControlModeIndicator 0-3, 8-8;
SG_MUL_VAL_ 2559835902 CommandECUInstance NMControlModeIndicator 0-3, 8-8;
SG_MUL_VAL_ 2559835902 CommandFunctionInstance NMControlModeIndicator 0-3, 8-8;
SG_MUL_VAL_ 2559835902 CommandFunction NMControlModeIndicator 0-3, 8-8;
SG_MUL_VAL_ 2559835902 CommandVehicleSystem NMControlModeIndicator 0-3, 8-8;
SG_MUL_VAL_ 2559835902 CommandIndustryGroup NMControlModeIndicator 0-3, 8-8;
SG_MUL_VAL_ 2559835902 CommandVehicleSystemInstance NMControlModeIndicator 0-3, 8-8;
SG_MUL_VAL_ 2559835902 CommandArbitraryAddressCapable NMControlModeIndicator 0-3, 8-8;
